[part 2 of 2: packages /ECUCompositionTypes to /EndToEndProtections]
AUTOSAR XML (schema 00050)
package /ECUCompositionTypes
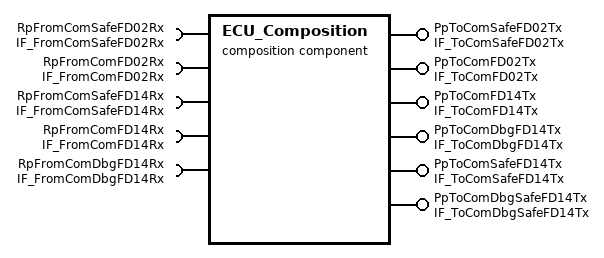
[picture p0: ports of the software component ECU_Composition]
  composition sw component type ECU_Composition
    5 x require port:
      RpFromComSafeFD02Rx: required-interface=IF_FromComSafeFD02Rx
        required-com-specs:
          data-element=PdlPosActual, init-value=1
          data-element=ASCM_Stat, init-value=0
          data-element=ASCM_SysFail, init-value=0
          data-element=ECM_THA_Resp, init-value=0
          data-element=ECM_TRSC_Resp, init-value=0
          data-element=EngineSts_W, init-value=3
          data-element=ESS_ENG_ST_W, init-value=15
          data-element=FL_Lvl, init-value=254
          data-element=FL_Lvl_Adj, init-value=0
          data-element=FR_Lvl, init-value=254
          data-element=FR_Lvl_Adj, init-value=0
          data-element=GearEngagedForDisplay, init-value=31
          data-element=HU_TRSC_EnableBtn_Sts, init-value=0
          data-element=RL_Lvl, init-value=254
          data-element=RL_Lvl_Adj, init-value=0
          data-element=RR_Lvl, init-value=254
          data-element=RR_Lvl_Adj, init-value=0
          {data-element=VIN_DATA, init-value=[rule-based-values={rule=FILL_UNTIL_END, rule-arguments=0}]}
          data-element=VIN_MSG, init-value=3
          data-element=Active_Park_Mode, init-value=0
          data-element=Active_Park_Prox_Chime, init-value=0
          data-element=APARequestSts, init-value=0
          data-element=Backup_Cam_Delay, init-value=0
          data-element=Brk_Stat, init-value=0
          data-element=CmdIgnSts, init-value=0
          data-element=DriverDoorSts, init-value=0
          data-element=DynamicGrid, init-value=1
          data-element=ExternalTemperature, init-value=0
          data-element=FT_PAMRequestSts, init-value=0
          data-element=Fwrd_Cam_Guidelines, init-value=0
          data-element=GearEngaged, init-value=0
          data-element=HAS_Status_C2, init-value=0
          data-element=LanguageSelection, init-value=0
          data-element=LatAcceleration_BSM, init-value=4095
          data-element=LHRDoorSts, init-value=0
          data-element=LongAcceleration_BSM, init-value=4095
          data-element=LwsAngle, init-value=0
          data-element=LwsAngleType, init-value=0
          data-element=LwsSpeed, init-value=0
          data-element=MRM_STATUS_C2, init-value=0
          data-element=PamChimeVolumeFront, init-value=1
          data-element=PamChimeVolumeRear, init-value=1
          data-element=PAMRequestSts, init-value=0
          data-element=PsngrDoorSts, init-value=0
          data-element=Rear_Brk_Asst, init-value=0
          data-element=RHatchSts, init-value=0
          data-element=RHRDoorSts, init-value=0
          data-element=ShiftLeverPosition, init-value=0
          data-element=SVC_Guidelines, init-value=0
          data-element=TargetGear, init-value=15
          data-element=TCASERANGESTATUS, init-value=0
          data-element=TGW_CAMERA_DISP_STAT, init-value=0
          data-element=TrailerConnectionSts, init-value=0
          data-element=TRANS_ADAS_Inhibit, init-value=0
          data-element=TransmissionSailingSts, init-value=0
          data-element=VehicleSpeedVSOSig, init-value=0
          data-element=YawRate_BSM, init-value=4095
          data-element=CameraDisplaySts2, init-value=0
          data-element=CM_TCH_STAT, init-value=0
          data-element=CM_TCH_X_COORD, init-value=0
          data-element=CM_TCH_Y_COORD, init-value=0
          data-element=ITBM_TrlrStat, init-value=0
          data-element=Shifter_ADAS_Inhibit, init-value=0
          data-element=ShiftLeverPositionReq, init-value=0
          data-element=EPS_SteeringTouchStat, init-value=0
          data-element=EPS_SteeringTouq_Resp, init-value=0
          data-element=EPS_THA_DriverTorqueOverride, init-value=0
          data-element=EPS_THA_SteeringTorqueResp, init-value=0
          data-element=THA_SteeringTouchStat, init-value=0
      RpFromComFD02Rx: required-interface=IF_FromComFD02Rx
        required-com-specs:
          data-element=Altitude_RMSE_C2, init-value=255
          data-element=Battery_Volt_1, init-value=0
          data-element=BSM_THA_Brk_Resp, init-value=0
          data-element=CurrentCanNMState_FD01_BCM, init-value=0
          data-element=CurrentCanNMState_FD01_SGW, init-value=0
          data-element=CurrentCanNMState_FD02_BCM, init-value=0
          data-element=CurrentCanNMState_FD02_BSM2, init-value=0
          data-element=CurrentCanNMState_FD02_CADM2, init-value=0
          data-element=CurrentCanNMState_FD02_EPS, init-value=0
          data-element=CurrentCanNMState_FD02_ORC, init-value=0
          data-element=CurrentCanNMState_FD02_SGW, init-value=0
          data-element=CurrentCanNMState_FD02_TRLR_REV, init-value=0
          data-element=CurrentCanNMState_FD03_BCM, init-value=0
          data-element=CurrentCanNMState_FD03_SGW, init-value=0
          data-element=CurrentCanNMState_FD04_BCM, init-value=0
          data-element=CurrentCanNMState_FD08_SGW, init-value=0
          data-element=CurrentCanNMState_FD11_SGW, init-value=0
          data-element=CurrentFailSts_FD01_BCM, init-value=0
          data-element=CurrentFailSts_FD01_SGW, init-value=0
          data-element=CurrentFailSts_FD02_BCM, init-value=0
          data-element=CurrentFailSts_FD02_BSM2, init-value=0
          data-element=CurrentFailSts_FD02_CADM2, init-value=0
          data-element=CurrentFailSts_FD02_EPS, init-value=0
          data-element=CurrentFailSts_FD02_ORC, init-value=0
          data-element=CurrentFailSts_FD02_SGW, init-value=0
          data-element=CurrentFailSts_FD02_TRLR_REV, init-value=0
          data-element=CurrentFailSts_FD03_BCM, init-value=0
          data-element=CurrentFailSts_FD03_SGW, init-value=0
          data-element=CurrentFailSts_FD04_BCM, init-value=0
          data-element=CurrentFailSts_FD08_SGW, init-value=0
          data-element=CurrentFailSts_FD11_SGW, init-value=0
          data-element=DeltaTimestamp_IMUdata, init-value=255
          data-element=DES_FD01_BCM, init-value=0
          data-element=DES_FD01_SGW, init-value=0
          data-element=DES_FD02_BCM, init-value=0
          data-element=DES_FD02_BSM2, init-value=0
          data-element=DES_FD02_CADM2, init-value=0
          data-element=DES_FD02_EPS, init-value=0
          data-element=DES_FD02_ORC, init-value=0
          data-element=DES_FD02_SGW, init-value=0
          data-element=DES_FD02_TRLR_REV, init-value=0
          data-element=DES_FD03_BCM, init-value=0
          data-element=DES_FD03_SGW, init-value=0
          data-element=DES_FD04_BCM, init-value=0
          data-element=DES_FD08_SGW, init-value=0
          data-element=DES_FD11_SGW, init-value=0
          data-element=Digit_{01..11}, init-value=0
          data-element=EOL_FD01_BCM, init-value=0
          data-element=EOL_FD01_SGW, init-value=0
          data-element=EOL_FD02_BCM, init-value=0
          data-element=EOL_FD02_BSM2, init-value=0
          data-element=EOL_FD02_CADM2, init-value=0
          data-element=EOL_FD02_EPS, init-value=0
          data-element=EOL_FD02_ORC, init-value=0
          data-element=EOL_FD02_SGW, init-value=0
          data-element=EOL_FD02_TRLR_REV, init-value=0
          data-element=EOL_FD03_BCM, init-value=0
          data-element=EOL_FD03_SGW, init-value=0
          data-element=EOL_FD04_BCM, init-value=0
          data-element=EOL_FD08_SGW, init-value=0
          data-element=EOL_FD11_SGW, init-value=0
          data-element=EPBSts, init-value=0
          data-element=GenericFailSts_FD01_BCM, init-value=0
          data-element=GenericFailSts_FD01_SGW, init-value=0
          data-element=GenericFailSts_FD02_BCM, init-value=0
          data-element=GenericFailSts_FD02_BSM2, init-value=0
          data-element=GenericFailSts_FD02_CADM2, init-value=0
          data-element=GenericFailSts_FD02_EPS, init-value=0
          data-element=GenericFailSts_FD02_ORC, init-value=0
          data-element=GenericFailSts_FD02_SGW, init-value=0
          data-element=GenericFailSts_FD02_TRLR_REV, init-value=0
          data-element=GenericFailSts_FD03_BCM, init-value=0
          data-element=GenericFailSts_FD03_SGW, init-value=0
          data-element=GenericFailSts_FD04_BCM, init-value=0
          data-element=GenericFailSts_FD08_SGW, init-value=0
          data-element=GenericFailSts_FD11_SGW, init-value=0
          data-element=Heading_Angle_C2, init-value=65535
          data-element=IgnitionOnCounter, init-value=0
          data-element=LatAcceleration_C2, init-value=4095
          data-element=LatAccelerationOffset_BSM, init-value=255
          data-element=Latitude_RMSE_C2, init-value=255
          data-element=LHF_FastPulseCounter, init-value=0
          data-element=LHF_Spin, init-value=0
          data-element=LHFWheelSpeed, init-value=0
          data-element=LHR_FastPulseCounter, init-value=0
          data-element=LHR_Spin, init-value=0
          data-element=LHRWheelSpeed, init-value=0
          data-element=LongAcceleration_C2, init-value=4095
          data-element=LongAccelerationOffset_BSM, init-value=255
          data-element=Longitude_RMSE_C2, init-value=255
          data-element=OperationalModeSts, init-value=0
          data-element=Pitch_RMSE_C2, init-value=255
          data-element=PitchRate_C2, init-value=4095
          data-element=PreviousCanNMState_FD01_BCM, init-value=0
          data-element=PreviousCanNMState_FD01_SGW, init-value=0
          data-element=PreviousCanNMState_FD02_BCM, init-value=0
          data-element=PreviousCanNMState_FD02_BSM2, init-value=0
          data-element=PreviousCanNMState_FD02_CADM2, init-value=0
          data-element=PreviousCanNMState_FD02_EPS, init-value=0
          data-element=PreviousCanNMState_FD02_ORC, init-value=0
          data-element=PreviousCanNMState_FD02_SGW, init-value=0
          data-element=PreviousCanNMState_FD02_TRLR_REV, init-value=0
          data-element=PreviousCanNMState_FD03_BCM, init-value=0
          data-element=PreviousCanNMState_FD03_SGW, init-value=0
          data-element=PreviousCanNMState_FD04_BCM, init-value=0
          data-element=PreviousCanNMState_FD08_SGW, init-value=0
          data-element=PreviousCanNMState_FD11_SGW, init-value=0
          data-element=REF_VEH_SPEED, init-value=1023
          data-element=RemStActvSts, init-value=0
          data-element=RHF_FastPulseCounter, init-value=0
          data-element=RHF_Spin, init-value=0
          data-element=RHFWheelSpeed, init-value=0
          data-element=RHR_FastPulseCounter, init-value=0
          data-element=RHR_Spin, init-value=0
          data-element=RHRWheelSpeed, init-value=0
          data-element=Roll_RMSE_C2, init-value=255
          data-element=RollRate_C2, init-value=4095
          data-element=SBR1RowDriverSeatSts, init-value=3
          data-element=StayActiveSource_FD01_BCM, init-value=0
          data-element=StayActiveSource_FD01_SGW, init-value=0
          data-element=StayActiveSource_FD02_BCM, init-value=0
          data-element=StayActiveSource_FD02_BSM2, init-value=0
          data-element=StayActiveSource_FD02_CADM2, init-value=0
          data-element=StayActiveSource_FD02_EPS, init-value=0
          data-element=StayActiveSource_FD02_ORC, init-value=0
          data-element=StayActiveSource_FD02_SGW, init-value=0
          data-element=StayActiveSource_FD02_TRLR_REV, init-value=0
          data-element=StayActiveSource_FD03_BCM, init-value=0
          data-element=StayActiveSource_FD03_SGW, init-value=0
          data-element=StayActiveSource_FD04_BCM, init-value=0
          data-element=StayActiveSource_FD08_SGW, init-value=0
          data-element=StayActiveSource_FD11_SGW, init-value=0
          data-element=TotalOdometer, init-value=0
          data-element=TRSC_CenterBtn_Sts, init-value=0
          data-element=TRSC_EnableBtn_Sts, init-value=0
          data-element=TRSC_RawKnob, init-value=0
          data-element=TurnIndicatorSts, init-value=0
          data-element=VehicleStandStillSts, init-value=1
          data-element=VerticalAcceleration_C2, init-value=4095
          data-element=WakeupSource_FD01_ADCM, init-value=0
          data-element=WakeupSource_FD01_BCM, init-value=0
          data-element=WakeupSource_FD01_SGW, init-value=0
          data-element=WakeupSource_FD02_BCM, init-value=0
          data-element=WakeupSource_FD02_BSM2, init-value=0
          data-element=WakeupSource_FD02_CADM2, init-value=0
          data-element=WakeupSource_FD02_EPS, init-value=0
          data-element=WakeupSource_FD02_ORC, init-value=0
          data-element=WakeupSource_FD02_SGW, init-value=0
          data-element=WakeupSource_FD02_TRLR_REV, init-value=0
          data-element=WakeupSource_FD03_BCM, init-value=0
          data-element=WakeupSource_FD03_SGW, init-value=0
          data-element=WakeupSource_FD04_BCM, init-value=0
          data-element=WakeupSource_FD08_SGW, init-value=0
          data-element=WakeupSource_FD11_SGW, init-value=0
          data-element=YawRate_C2, init-value=4095
          data-element=YawRate_RMSE_C2, init-value=255
      RpFromComSafeFD14Rx: required-interface=IF_FromComSafeFD14Rx
        required-com-specs:
          data-element=FD14_PdlPosActual, init-value=1
          data-element=FD14_ECM_THA_Resp, init-value=0
          data-element=FD14_ECM_TRSC_Resp, init-value=0
          data-element=FD14_EngineSts_W, init-value=3
          data-element=FD14_ESS_ENG_ST_W, init-value=15
          data-element=FD14_ACC_Systemsts, init-value=0
          data-element=FD14_Brk_Stat, init-value=0
          data-element=FD14_BrkPdl_Stat, init-value=3
          data-element=FD14_BrkTrq, init-value=32767
          data-element=FD14_BrkTrq_Driver, init-value=32767
          data-element=FD14_BSM_THA_Brk_Resp, init-value=0
          data-element=FD14_EPBSts, init-value=0
          data-element=FD14_EPS_HandsOnRecognition, init-value=0
          data-element=FD14_ESC_TRSC_Brk_Resp, init-value=0
          data-element=FD14_ExternalBrkRequestsDisabled, init-value=0
          data-element=FD14_HAS_Status, init-value=0
          data-element=FD14_LatAcceleration_BSM, init-value=4095
          data-element=FD14_LatAccelerationFailSts_BSM, init-value=0
          data-element=FD14_LatAccelerationOffset_BSM, init-value=255
          data-element=FD14_LHF_FastPulseCounter, init-value=0
          data-element=FD14_LHF_Spin, init-value=0
          data-element=FD14_LHF_WheelSensorFailSts, init-value=0
          data-element=FD14_LHFWheelSpeed, init-value=0
          data-element=FD14_LHR_FastPulseCounter, init-value=0
          data-element=FD14_LHR_Spin, init-value=0
          data-element=FD14_LHR_WheelSensorFailSts, init-value=0
          data-element=FD14_LHRWheelSpeed, init-value=0
          data-element=FD14_LongAcceleration_BSM, init-value=4095
          data-element=FD14_LongAccelerationFailSts_BSM, init-value=0
          data-element=FD14_LongAccelerationOffset_BSM, init-value=255
          data-element=FD14_LwsAngle, init-value=0
          data-element=FD14_LwsAngleType, init-value=0
          data-element=FD14_LwsSpeed, init-value=0
          data-element=FD14_PAM_Brk_Rq_RspSts, init-value=0
          data-element=FD14_ParkingGearShiftReq_BSM, init-value=0
          data-element=FD14_ParkingInterventionSts, init-value=0
          data-element=FD14_REF_VEH_SPEED, init-value=1023
          data-element=FD14_RHF_FastPulseCounter, init-value=0
          data-element=FD14_RHF_Spin, init-value=0
          data-element=FD14_RHF_WheelSensorFailSts, init-value=0
          data-element=FD14_RHFWheelSpeed, init-value=0
          data-element=FD14_RHR_FastPulseCounter, init-value=0
          data-element=FD14_RHR_Spin, init-value=0
          data-element=FD14_RHR_WheelSensorFailSts, init-value=0
          data-element=FD14_RHRWheelSpeed, init-value=0
          data-element=FD14_Slope, init-value=0
          data-element=FD14_SPM_Lat_Ctrl_ResponseSts, init-value=0
          data-element=FD14_Steering_Column_Torque, init-value=0
          data-element=FD14_VehicleSpeedVSOSig, init-value=0
          data-element=FD14_VehicleSpeedVSOSig_B2, init-value=0
          data-element=FD14_VehicleStandStillSts, init-value=1
          data-element=FD14_YawRate_BSM, init-value=4095
          data-element=FD14_YawRateFailSts_BSM, init-value=0
          data-element=FD14_EPS_SteeringTouchStat, init-value=0
          data-element=FD14_EPS_SteeringTouq_Resp, init-value=0
          data-element=FD14_EPS_THA_DriverTorqueOverride, init-value=0
          data-element=FD14_EPS_THA_SteeringTorqueResp, init-value=0
          data-element=FD14_THA_SteeringTouchStat, init-value=0
      RpFromComFD14Rx: required-interface=IF_FromComFD14Rx
        required-com-specs:
          data-element=FD14_Accel_Pedal_Override, init-value=0
          data-element=FD14_DriverReq_AxleTrq_Enabled_BSM, init-value=0
          data-element=FD14_PPPA_TrqEnblRq_Allowed, init-value=0
      RpFromComDbgFD14Rx: required-interface=IF_FromComDbgFD14Rx
        required-com-specs:
          {data-element=FD14_RawPntDebugSignal, init-value=[rule-based-values={rule=FILL_UNTIL_END, rule-arguments=0}]}
          data-element=FD14_UssParkingModeSignal, init-value=0
    6 x provide port:
      PpToComSafeFD02Tx: provided-interface=IF_ToComSafeFD02Tx
        provided-com-specs:
          data-element=Reserved_for_functional_safety, init-value=0
          data-element=Segment_1_Confidence, init-value=0
          data-element=Segment_1_ID, init-value=0
          data-element=Segment_1_X1, init-value=0
          data-element=Segment_1_X2, init-value=0
          data-element=Segment_1_Y1, init-value=0
          data-element=Segment_1_Y2, init-value=0
          data-element=Segment_2_Confidence, init-value=0
          data-element=Segment_2_ID, init-value=0
          data-element=Segment_2_X1, init-value=0
          data-element=Segment_2_X2, init-value=0
          data-element=Segment_2_Y1, init-value=0
          data-element=Segment_2_Y2, init-value=0
          data-element=Segment_3_Confidence, init-value=0
          data-element=Segment_3_ID, init-value=0
          data-element=Segment_3_X1, init-value=0
          data-element=Segment_3_X2, init-value=0
          data-element=Segment_3_Y1, init-value=0
          data-element=Segment_3_Y2, init-value=0
          data-element=Segment_4_Confidence, init-value=0
          data-element=Segment_4_ID, init-value=0
          data-element=Segment_4_X1, init-value=0
          data-element=Segment_4_X2, init-value=0
          data-element=Segment_4_Y1, init-value=0
          data-element=Segment_4_Y2, init-value=0
          data-element=Segment_5_Confidence, init-value=0
          data-element=Segment_5_ID, init-value=0
          data-element=Segment_5_X1, init-value=0
          data-element=Segment_5_X2, init-value=0
          data-element=Segment_5_Y1, init-value=0
          data-element=Segment_5_Y2, init-value=0
          data-element=Segment_6_Confidence, init-value=0
          data-element=Segment_6_ID, init-value=0
          data-element=Segment_6_X1, init-value=0
          data-element=Segment_6_X2, init-value=0
          data-element=Segment_6_Y1, init-value=0
          data-element=Segment_6_Y2, init-value=0
          data-element=Segment_7_Confidence, init-value=0
          data-element=Segment_7_ID, init-value=0
          data-element=Segment_7_X1, init-value=0
          data-element=Segment_7_X2, init-value=0
          data-element=Segment_7_Y1, init-value=0
          data-element=Segment_7_Y2, init-value=0
          data-element=Segment_8_Confidence, init-value=0
          data-element=Segment_8_ID, init-value=0
          data-element=Segment_8_X1, init-value=0
          data-element=Segment_8_X2, init-value=0
          data-element=Segment_8_Y1, init-value=0
          data-element=Segment_8_Y2, init-value=0
          data-element=Camera_Status, init-value=0
          data-element=Cntr_ADAS_FD_LANES_1, init-value=0
          data-element=Cntr_ADAS_FD_LANES_2, init-value=0
          data-element=FOD_Confidence, init-value=0
          data-element=Frame_Index_Lanes_1, init-value=0
          data-element=Frame_Index_Lanes_2, init-value=0
          data-element=Health_Front_Object_Detection, init-value=0
          data-element=Health_Lane_Detection, init-value=0
          data-element=Line_1_Confidence, init-value=0
          data-element=Line_1_Curvature, init-value=0
          data-element=Line_1_Curvature_Rate, init-value=0
          data-element=Line_1_End_Range, init-value=0
          data-element=Line_1_Heading, init-value=0
          data-element=Line_1_Offset, init-value=0
          data-element=Line_1_Start_Range, init-value=0
          data-element=Line_1_Type, init-value=0
          data-element=Line_2_Confidence, init-value=0
          data-element=Line_2_Curvature, init-value=0
          data-element=Line_2_Curvature_Rate, init-value=0
          data-element=Line_2_End_Range, init-value=0
          data-element=Line_2_Heading, init-value=0
          data-element=Line_2_Offset, init-value=0
          data-element=Line_2_Start_Range, init-value=0
          data-element=Line_2_Type, init-value=0
          data-element=Line_3_Confidence, init-value=0
          data-element=Line_3_Curvature, init-value=0
          data-element=Line_3_Curvature_Rate, init-value=0
          data-element=Line_3_End_Range, init-value=0
          data-element=Line_3_Heading, init-value=0
          data-element=Line_3_Offset, init-value=0
          data-element=Line_3_Start_Range, init-value=0
          data-element=Line_3_Type, init-value=0
          data-element=Line_4_Confidence, init-value=0
          data-element=Line_4_Curvature, init-value=0
          data-element=Line_4_Curvature_Rate, init-value=0
          data-element=Line_4_End_Range, init-value=0
          data-element=Line_4_Heading, init-value=0
          data-element=Line_4_Offset, init-value=0
          data-element=Line_4_Start_Range, init-value=0
          data-element=Line_4_Type, init-value=0
          {data-element=MAC_ADAS_FD_LANES_1, init-value=[rule-based-values={rule=FILL_UNTIL_END, rule-arguments=0}]}
          {data-element=MAC_ADAS_FD_LANES_2, init-value=[rule-based-values={rule=FILL_UNTIL_END, rule-arguments=0}]}
          data-element=Alert_CHF, init-value=0
          data-element=Alert_CHR, init-value=0
          data-element=Alert_LHF, init-value=0
          data-element=Alert_LHR, init-value=0
          data-element=Alert_RHF, init-value=0
          data-element=Alert_RHR, init-value=0
          data-element=AUXCamsRQSts, init-value=0
          data-element=ChimeActivation_LHF, init-value=0
          data-element=ChimeActivation_LHR, init-value=0
          data-element=ChimeActivation_RHF, init-value=0
          data-element=ChimeActivation_RHR, init-value=0
          data-element=DisplayView2, init-value=0
          data-element=FrontSensorSts, init-value=0
          data-element=FT_PAM_LedControlSts, init-value=0
          data-element=Graphic_CHF, init-value=0
          data-element=Graphic_CHR, init-value=0
          data-element=Graphic_LHF, init-value=0
          data-element=Graphic_LHR, init-value=0
          data-element=Graphic_RHF, init-value=0
          data-element=Graphic_RHR, init-value=0
          data-element=HMICode, init-value=0
          data-element=ImageDefeatRQSts, init-value=0
          data-element=MoreCamsRQSts, init-value=0
          data-element=PAM_CHIME_REP_RATESts, init-value=0
          data-element=PAM_CHIME_TYPE, init-value=0
          data-element=PAM_LedControlSts, init-value=0
          data-element=PAM_Off_Status, init-value=0
          data-element=PAM_Off_Status_2BT, init-value=0
          data-element=PAM_PopUpRqst, init-value=0
          data-element=PAM_Volume, init-value=0
          data-element=PAMSystemFault, init-value=0
          data-element=ParkingManeuverActive, init-value=0
          data-element=PPPA_TurnIndicatorRqst, init-value=0
          data-element=RearSensorSts, init-value=0
          data-element=RR_PAM_Brk_RqSts, init-value=0
          data-element=RR_PAM_Dist, init-value=0
          data-element=RR_PAM_StopControlSts, init-value=0
          data-element=SPM_LedControlSts, init-value=0
          data-element=SPM_Screen_Rqst, init-value=0
          data-element=SPMControlSts, init-value=0
          data-element=SPMFailSts, init-value=0
          data-element=SPMSystemFault, init-value=0
          data-element=TRSC_LED_Stat, init-value=0
      PpToComFD02Tx: provided-interface=IF_ToComFD02Tx
        provided-com-specs:
          data-element=CurrentCanNMState_FD02_PAM, init-value=0
          data-element=CurrentFailSts_FD02_PAM, init-value=0
          data-element=DES_FD02_PAM, init-value=0
          data-element=Digit_{01..11}_PAM, init-value=0
          data-element=EOL_FD02_PAM, init-value=0
          data-element=GenericFailSts_FD02_PAM, init-value=0
          {data-element=N_PDU, init-value=[rule-based-values={rule=FILL_UNTIL_END, rule-arguments=0}]}
          data-element=PreviousCanNMState_FD02_PAM, init-value=0
          {data-element=StayActiveSource_FD02_PAM, init-value=[rule-based-values={rule=FILL_UNTIL_END, rule-arguments=0}]}
          data-element=THA_EPB_Req, init-value=0
          data-element=THA_Speed_Limit, init-value=0
          data-element=THA_SpeedLimit_Req, init-value=0
          data-element=THA_STAT, init-value=0
          data-element=THA_SteeringDamping, init-value=78.125
          data-element=THA_SteeringTorqueInfo, init-value=0
          data-element=THA_SteeringTorqueReq, init-value=0
          data-element=Trailer_Angle, init-value=0
          data-element=Trailer_Angle_Sign, init-value=0
          data-element=Trailer_Calibration, init-value=0
          data-element=TrlrHitchLight_Cntrl, init-value=0
          data-element=TRSC_PopupDisp_Info, init-value=0
          data-element=TRSC_SpeedLimit_Req, init-value=0
          data-element=TRSC_STAT, init-value=1
          data-element=TRSC_SteeringDamping, init-value=100
          data-element=TRSC_SteeringTorqueInfo, init-value=0
          data-element=TRSC_SteeringTorqueReq, init-value=0
          data-element=TRSC_VehicleStop_Req, init-value=3
          data-element=TRSCMoreCamRQSts, init-value=0
          data-element=WakeupSource_FD02_PAM, init-value=0
          data-element=TRSC_PopupDisp_Info2, init-value=0
      PpToComFD14Tx: provided-interface=IF_ToComFD14Tx
        provided-com-specs:
          data-element=FD14_THA_EPB_Req, init-value=0
          data-element=FD14_THA_Speed_Limit, init-value=0
          data-element=FD14_THA_SpeedLimit_Req, init-value=0
          data-element=FD14_THA_STAT, init-value=0
          data-element=FD14_THA_SteeringDamping, init-value=100
          data-element=FD14_THA_SteeringTorqueInfo, init-value=1024
          data-element=FD14_THA_SteeringTorqueReq, init-value=0
          data-element=FD14_TRSC_SpeedLimit_Req, init-value=0
          data-element=FD14_TRSC_STAT, init-value=1
          data-element=FD14_TRSC_SteeringDamping, init-value=100
          data-element=FD14_TRSC_SteeringTorqueInfo, init-value=1024
          data-element=FD14_TRSC_SteeringTorqueReq, init-value=0
          data-element=FD14_TRSC_VehicleStop_Req, init-value=3
      PpToComDbgFD14Tx: provided-interface=IF_ToComDbgFD14Tx
        provided-com-specs:
          FD14_ZoomPlusIcon_b
          FD14_ZoomMinusIcon_b
          FD14_ZoomFactor_u8
          FD14_ZoomButtonDisable_b
          FD14_Z_f32_EOL_Right
          FD14_Z_f32_EOL_Rear
          FD14_Z_f32_EOL_Left
          FD14_Z_f32_EOL_Front
          FD14_Z_f32_Current_Right
          FD14_Z_f32_Current_Rear
          FD14_Yaw_f32_SC_Right
          FD14_Yaw_f32_SC_Rear
          FD14_Yaw_f32_SC_Left
          FD14_Yaw_f32_SC_Front
          FD14_Yaw_f32_OC_Right
          FD14_Yaw_f32_OC_Rear
          FD14_Yaw_f32_OC_Left
          FD14_Yaw_f32_OC_Front
          FD14_Yaw_f32_EOL_Right
          FD14_Yaw_f32_EOL_Rear
          FD14_Yaw_f32_EOL_Left
          FD14_Yaw_f32_EOL_Front
          FD14_Yaw_f32_Current_Right
          FD14_Yaw_f32_Current_Rear
          FD14_Y_f32_EOL_Right
          FD14_Y_f32_EOL_Rear
          FD14_Y_f32_EOL_Left
          FD14_Y_f32_EOL_Front
          FD14_Y_f32_Current_Right
          FD14_Y_f32_Current_Rear
          FD14_XIcon_b
          FD14_X_f32_EOL_Right
          FD14_X_f32_EOL_Rear
          FD14_X_f32_EOL_Left
          FD14_X_f32_EOL_Front
          FD14_X_f32_Current_Right
          FD14_X_f32_Current_Rear
          FD14_X_BTN_PRESSED_b
          FD14_View_Error_e
          FD14_vehicleSpeed_f32
          FD14_vehicleLine_e
          FD14_ValidFeatures_Right_u32
          FD14_ValidFeatures_Rear_u32
          FD14_ValidFeatures_Left_u32
          FD14_ValidFeatures_Front_u32
          FD14_USS_MPAZoneF03
          FD14_USS_MPAZoneF02
          FD14_USS_MPAZoneF01
          FD14_USS_MPAZoneF00
          FD14_USS_MPAZoneB03
          FD14_USS_MPAZoneB02
          FD14_USS_MPAZoneB01
          FD14_USS_MPAZoneB00
          FD14_turnaroundSubState
          FD14_Tstr_SD_RSR_Unfiltered_DirDist2
          FD14_Tstr_SD_RSR_Unfiltered_DirDist1
          FD14_Tstr_SD_RSR_SensorBlkgSetCounter
          FD14_Tstr_SD_RSR_SensorBlkgClrCounter
          FD14_Tstr_SD_RSR_Ringtime_us
          FD14_Tstr_SD_RSR_RingFreq
          FD14_Tstr_SD_RSR_EchoHeight_adc
          FD14_Tstr_SD_RSR_DrvFreq
          FD14_Tstr_SD_RSL_Unfiltered_DirDist2
          FD14_Tstr_SD_RSL_Unfiltered_DirDist1
          FD14_Tstr_SD_RSL_SensorBlkgSetCounter
          FD14_Tstr_SD_RSL_SensorBlkgClrCounter
          FD14_Tstr_SD_RSL_Ringtime_us
          FD14_Tstr_SD_RSL_RingFreq
          FD14_Tstr_SD_RSL_EchoHeight_adc
          FD14_Tstr_SD_RSL_DrvFreq
          FD14_Tstr_SD_ROR_Unfiltered_DirDist2
          FD14_Tstr_SD_ROR_Unfiltered_DirDist1
          FD14_Tstr_SD_ROR_SensorBlkgSetCounter
          FD14_Tstr_SD_ROR_SensorBlkgClrCounter
          FD14_Tstr_SD_ROR_Ringtime_us
          FD14_Tstr_SD_ROR_RingFreq
          FD14_Tstr_SD_ROR_EchoHeight_adc
          FD14_Tstr_SD_ROR_DrvFreq
          FD14_Tstr_SD_ROL_Unfiltered_DirDist2
          FD14_Tstr_SD_ROL_Unfiltered_DirDist1
          FD14_Tstr_SD_ROL_SensorBlkgSetCounter
          FD14_Tstr_SD_ROL_SensorBlkgClrCounter
          FD14_Tstr_SD_ROL_Ringtime_us
          FD14_Tstr_SD_ROL_RingFreq
          FD14_Tstr_SD_ROL_EchoHeight_adc
          FD14_Tstr_SD_ROL_DrvFreq
          FD14_Tstr_SD_RIR_Unfiltered_DirDist2
          FD14_Tstr_SD_RIR_Unfiltered_DirDist1
          FD14_Tstr_SD_RIR_SensorBlkgSetCounter
          FD14_Tstr_SD_RIR_SensorBlkgClrCounter
          FD14_Tstr_SD_RIR_Ringtime_us
          FD14_Tstr_SD_RIR_RingFreq
          FD14_Tstr_SD_RIR_EchoHeight_adc
          FD14_Tstr_SD_RIR_DrvFreq
          FD14_Tstr_SD_RIL_Unfiltered_DirDist2
          FD14_Tstr_SD_RIL_Unfiltered_DirDist1
          FD14_Tstr_SD_RIL_SensorBlkgSetCounter
          FD14_Tstr_SD_RIL_SensorBlkgClrCounter
          FD14_Tstr_SD_RIL_Ringtime_us
          FD14_Tstr_SD_RIL_RingFreq
          FD14_Tstr_SD_RIL_EchoHeight_adc
          FD14_Tstr_SD_RIL_DrvFreq
          FD14_Tstr_SD_FSR_Unfiltered_DirDist2
          FD14_Tstr_SD_FSR_Unfiltered_DirDist1
          FD14_Tstr_SD_FSR_SensorBlkgSetCounter
          FD14_Tstr_SD_FSR_SensorBlkgClrCounter
          FD14_Tstr_SD_FSR_Ringtime_us
          FD14_Tstr_SD_FSR_RingFreq
          FD14_Tstr_SD_FSR_EchoHeight_adc
          FD14_Tstr_SD_FSR_DrvFreq
          FD14_Tstr_SD_FSL_Unfiltered_DirDist2
          FD14_Tstr_SD_FSL_Unfiltered_DirDist1
          FD14_Tstr_SD_FSL_SensorBlkgSetCounter
          FD14_Tstr_SD_FSL_SensorBlkgClrCounter
          FD14_Tstr_SD_FSL_Ringtime_us
          FD14_Tstr_SD_FSL_RingFreq
          FD14_Tstr_SD_FSL_EchoHeight_adc
          FD14_Tstr_SD_FSL_DrvFreq
          FD14_Tstr_SD_FOR_Unfiltered_DirDist2
          FD14_Tstr_SD_FOR_Unfiltered_DirDist1
          FD14_Tstr_SD_FOR_SensorBlkgSetCounter
          FD14_Tstr_SD_FOR_SensorBlkgClrCounter
          FD14_Tstr_SD_FOR_Ringtime_us
          FD14_Tstr_SD_FOR_RingFreq
          FD14_Tstr_SD_FOR_EchoHeight_adc
          FD14_Tstr_SD_FOR_DrvFreq
          FD14_Tstr_SD_FOL_Unfiltered_DirDist2
          FD14_Tstr_SD_FOL_Unfiltered_DirDist1
          FD14_Tstr_SD_FOL_SensorBlkgSetCounter
          FD14_Tstr_SD_FOL_SensorBlkgClrCounter
          FD14_Tstr_SD_FOL_Ringtime_us
          FD14_Tstr_SD_FOL_RingFreq
          FD14_Tstr_SD_FOL_EchoHeight_adc
          FD14_Tstr_SD_FOL_DrvFreq
          FD14_Tstr_SD_FIR_Unfiltered_DirDist2
          FD14_Tstr_SD_FIR_Unfiltered_DirDist1
          FD14_Tstr_SD_FIR_SensorBlkgSetCounter
          FD14_Tstr_SD_FIR_SensorBlkgClrCounter
          FD14_Tstr_SD_FIR_Ringtime_us
          FD14_Tstr_SD_FIR_RingFreq
          FD14_Tstr_SD_FIR_EchoHeight_adc
          FD14_Tstr_SD_FIR_DrvFreq
          FD14_Tstr_SD_FIL_Unfiltered_DirDist2
          FD14_Tstr_SD_FIL_Unfiltered_DirDist1
          FD14_Tstr_SD_FIL_SensorBlkgSetCounter
          FD14_Tstr_SD_FIL_SensorBlkgClrCounter
          FD14_Tstr_SD_FIL_Ringtime_us
          FD14_Tstr_SD_FIL_RingFreq
          FD14_Tstr_SD_FIL_EchoHeight_adc
          FD14_Tstr_SD_FIL_DrvFreq
          FD14_TrscTrailerRed
          FD14_TrscStatus
          FD14_trscStat_e
          FD14_TrscOvl
          FD14_TrscJackKnifeRed
          FD14_TrscJackKnifeOrange
          FD14_transEquipped_e
          FD14_TrailerWheelBase
          FD14_TrailerConnectionStatus
          FD14_Trailercalinfo
          FD14_TrailerCalibrationStatus
          FD14_trailerCalibrationDelay
          FD14_trailerCalibrationCount
          FD14_TrailerCalFailInfo
          FD14_TrailerAngleSign
          FD14_trailerAngle
          FD14_Trailer_tracking_confidence
          FD14_Trailer_Recognition_Confidence
          FD14_Total_lines_count
          FD14_TopViewRearDynamics_b
          FD14_TopViewFrontDynamics_b
          FD14_TopViewBlack_b
          FD14_TopVideoBlanked_b
          FD14_TopRearButtonSelect_b
          FD14_TopRearButtonNoSelect_b
          FD14_TopFrontButtonSelect_b
          FD14_TopFrontButtonNoSelect_b
          FD14_TimeStamp_SystemStatus
          FD14_THATriangleOverlay
          FD14_THAStartButton
          FD14_THAProgressBar
          FD14_THACouplerBulletIcon
          FD14_THAConfirmButton
          FD14_THAButtonSelectable
          FD14_THAButtonGrey
          FD14_tgwDispStatus_e
          FD14_tchScrnStatus_e
          FD14_tchScrnCoord_s_Y_u16
          FD14_tchScrnCoord_s_X_u16
          FD14_TargetLimitRear_Right_s8
          FD14_TargetLimitRear_Rear_s8
          FD14_TargetLimitRear_Left_s8
          FD14_TargetLimitRear_Front_s8
          FD14_TargetLimitFront_Right_s8
          FD14_TargetLimitFront_Rear_s8
          FD14_TargetLimitFront_Left_s8
          FD14_TargetLimitFront_Front_s8
          FD14_TargetInit_Right_s8
          FD14_TargetInit_Rear_s8
          FD14_TargetInit_Left_s8
          FD14_TargetInit_Front_s8
          FD14_TargetDetectRightRear_Right_s8
          FD14_TargetDetectRightRear_Rear_s8
          FD14_TargetDetectRightRear_Left_s8
          FD14_TargetDetectRightRear_Front_s8
          FD14_TargetDetectRightFront_Right_s8
          FD14_TargetDetectRightFront_Rear_s8
          FD14_TargetDetectRightFront_Left_s8
          FD14_TargetDetectRightFront_Front_s8
          FD14_TargetDetectLeftRear_Right_s8
          FD14_TargetDetectLeftRear_Rear_s8
          FD14_TargetDetectLeftRear_Front_s8
          FD14_TargetDetectLeftFront_Right_s8
          FD14_TargetDetectLeftFront_Rear_s8
          FD14_TargetDetectLeftFront_Left_s8
          FD14_TargetDetectLeftFront_Front_s8
          FD14_TADAngleRate
          FD14_TadAngle
          FD14_SystemStatus
          FD14_SystemMode
          FD14_SVC_Static_Gridlines_Feature_b
          FD14_SVC_FFCV_Gridlines_Feature_b
          FD14_SVC_Dynamic_Gridlines_Feature_b
          FD14_SVC_Delay_Feature_b
          FD14_stUSSParkingSlot6SlotValid
          FD14_stUSSParkingSlot5SlotValid
          FD14_stUSSParkingSlot4SlotValid
          FD14_stUSSParkingSlot4SlotType
          FD14_stUSSParkingSlot4RearRightY
          FD14_stUSSParkingSlot4RearRightX
          FD14_stUSSParkingSlot4FrontLeftY
          FD14_stUSSParkingSlot4FrontLeftX
          FD14_stUSSParkingSlot4DataSlotSide
          FD14_stUSSParkingSlot3SlotValid
          FD14_stUSSParkingSlot2SlotValid
          FD14_stUSSParkingSlot1SlotValid
          FD14_stUSSParkingSlot1SlotType
          FD14_stUSSParkingSlot1RearRightY
          FD14_stUSSParkingSlot1RearRightX
          FD14_stUSSParkingSlot1FrontLeftY
          FD14_stUSSParkingSlot1FrontLeftX
          FD14_stUSSParkingSlot1DataSlotSide
          FD14_stUSSParkingSlot1DataSlotID
          FD14_stUSSLockedSlotDataSlotValid
          FD14_stUSSLockedSlotDataSlotType
          FD14_stUSSLockedSlotDataSlotSide
          FD14_stUSSLockedSlotDataSlotID
          FD14_stUSSLockedSlotDataRearRightY
          FD14_stUSSLockedSlotDataRearRightX
          FD14_stUSSLockedSlotDataFrontLeftY
          FD14_stUSSLockedSlotDataFrontLeftX
          FD14_stRightObjectList4Valid
          FD14_stRightObjectList3Valid
          FD14_stRightObjectList2Valid
          FD14_stRightObjectList1Valid
          FD14_stPLDParkingSlot6SlotValid
          FD14_stPLDParkingSlot5SlotValid
          FD14_stPLDParkingSlot4SlotValid
          FD14_stPLDParkingSlot4SlotType
          FD14_stPLDParkingSlot4RearRightY
          FD14_stPLDParkingSlot4RearRightX
          FD14_stPLDParkingSlot4FrontLeftY
          FD14_stPLDParkingSlot4FrontLeftX
          FD14_stPLDParkingSlot4DataSlotSide
          FD14_stPLDParkingSlot4DataSlotID
          FD14_stPLDParkingSlot3SlotValid
          FD14_stPLDParkingSlot2SlotValid
          FD14_stPLDParkingSlot1SlotValid
          FD14_stPLDParkingSlot1SlotType
          FD14_stPLDParkingSlot1RearRightY
          FD14_stPLDParkingSlot1RearRightX
          FD14_stPLDParkingSlot1FrontLeftY
          FD14_stPLDParkingSlot1FrontLeftX
          FD14_stPLDParkingSlot1DataSlotSide
          FD14_stPLDParkingSlot1DataSlotID
          FD14_stPLDLockedSlotDataSlotValid
          FD14_stPLDLockedSlotDataSlotType
          FD14_stPLDLockedSlotDataSlotSide
          FD14_stPLDLockedSlotDataSlotID
          FD14_stPLDLockedSlotDataRearRightY
          FD14_stPLDLockedSlotDataRearRightX
          FD14_stPLDLockedSlotDataFrontLeftY
          FD14_stPLDLockedSlotDataFrontLeftX
          FD14_stnumPointsR
          FD14_stnumPointsL
          FD14_STM_v_TRGRIGHT_BTN_PRESSED_b
          FD14_STM_v_TRGLEFT_BTN_PRESSED_b
          FD14_STM_v_TRGAUTO_BTN_PRESSED_b
          FD14_stLeftObjectList4Valid
          FD14_stLeftObjectList3Valid
          FD14_stLeftObjectList2Valid
          FD14_stLeftObjectList1Valid
          FD14_stFPAInfoToVCLockedSlotValid
          FD14_stFPAInfoToVCLockedSlotType
          FD14_stFPAInfoToVCLockedSlotSide
          FD14_stFPAInfoToVCLockedSlotRearRghtY
          FD14_stFPAInfoToVCLockedSlotRearRghtX
          FD14_stFPAInfoToVCLockedSlotID
          FD14_stFPAInfoToVCLockedSlotFrntLeftY
          FD14_stFPAInfoToVCLockedSlotFrntLeftX
          FD14_stFPAInfoToHMISlot6Valid
          FD14_stFPAInfoToHMISlot5Valid
          FD14_stFPAInfoToHMISlot4Valid
          FD14_stFPAInfoToHMISlot3Valid
          FD14_stFPAInfoToHMISlot2Valid
          FD14_stFPAInfoToHMISlot1Valid
          FD14_steeringWheelAngle_f32
          FD14_SrvStAngIndOk_b
          FD14_SrvStAngIndNok_b
          FD14_SrvSpOmIndOk_b
          FD14_SrvSpOmIndNok_b
          FD14_SrvPrgBar80Per_b
          FD14_SrvPrgBar60Per_b
          FD14_SrvPrgBar40Per_b
          FD14_SrvPrgBar20Per_b
          FD14_SrvPrgBar100Per_b
          FD14_SrvPrgBar0Per_b
          FD14_SrvLayout_b
          FD14_SrvChkIndRun_b
          FD14_SrvChkIndOk_b
          FD14_SrvChkIndNok_b
          FD14_SrvChkIndCondNok_b
          FD14_SrvCamIndRiPend_b
          FD14_SrvCamIndRiOk_b
          FD14_SrvCamIndRiNone_b
          FD14_SrvCamIndRiNok_b
          FD14_SrvCamIndLePend_b
          FD14_SrvCamIndLeOk_b
          FD14_SrvCamIndLeNone_b
          FD14_SrvCamIndLeNok_b
          FD14_SrvCamIndFrPend_b
          FD14_SrvCamIndFrOk_b
          FD14_SrvCamIndFrNone_b
          FD14_SrvCamIndFrNok_b
          FD14_SrvCamIndBaPend_b
          FD14_SrvCamIndBaOk_b
          FD14_SrvCamIndBaNone_b
          FD14_SrvCamIndBaNok_b
          FD14_SoftBtn_Error_e
          FD14_SnrMeasDataChecksum
          FD14_SnrDat_sRSR_Indir_ROR_cm
          FD14_SnrDat_sRSL_Indir_ROL_cm
          FD14_SnrDat_sROR_Indir_RSR_cm
          FD14_SnrDat_sROR_Indir_RIR_cm
          FD14_SnrDat_sROL_Indir_RSL_cm
          FD14_SnrDat_sROL_Indir_RIL_cm
          FD14_SnrDat_sRIR_Indir_ROR_cm
          FD14_SnrDat_sRIR_Indir_RIL_cm
          FD14_SnrDat_sRIL_Indir_ROL_cm
          FD14_SnrDat_sRIL_Indir_RIR_cm
          FD14_SnrDat_sFSR_Indir_FOR_cm
          FD14_SnrDat_sFSL_Indir_FOL_cm
          FD14_SnrDat_sFOR_Indir_FSR_cm
          FD14_SnrDat_sFOR_Indir_FIR_cm
          FD14_SnrDat_sFOL_Indir_FSL_cm
          FD14_SnrDat_sFOL_Indir_FIL_cm
          FD14_SnrDat_sFIR_Indir_FOR_cm
          FD14_SnrDat_sFIR_Indir_FIL_cm
          FD14_SnrDat_sFIL_Indir_FOL_cm
          FD14_SnrDat_sFIL_Indir_FIR_cm
          FD14_SnrDat_RSR_Dir2_cm
          FD14_SnrDat_RSR_Dir1_cm
          FD14_SnrDat_RSL_Dir2_cm
          FD14_SnrDat_RSL_Dir1_cm
          FD14_SnrDat_ROR_Dir2_cm
          FD14_SnrDat_ROR_Dir1_cm
          FD14_SnrDat_ROL_Dir2_cm
          FD14_SnrDat_ROL_Dir1_cm
          FD14_SnrDat_RIR_Dir2_cm
          FD14_SnrDat_RIR_Dir1_cm
          FD14_SnrDat_RIL_Dir2_cm
          FD14_SnrDat_RIL_Dir1_cm
          FD14_SnrDat_FSR_Dir2_cm
          FD14_SnrDat_FSR_Dir1_cm
          FD14_SnrDat_FSL_Dir2_cm
          FD14_SnrDat_FSL_Dir1_cm
          FD14_SnrDat_FOR_Dir2_cm
          FD14_SnrDat_FOR_Dir1_cm
          FD14_SnrDat_FOL_Dir2_cm
          FD14_SnrDat_FOL_Dir1_cm
          FD14_SnrDat_FIR_Dir2_cm
          FD14_SnrDat_FIR_Dir1_cm
          FD14_SnrDat_FIL_Dir2_cm
          FD14_SnrDat_FIL_Dir1_cm
          FD14_slotSide
          FD14_SC_ModuleState_STM_Right
          FD14_SC_ModuleState_STM_Rear
          FD14_SC_ModuleState_STM_Left
          FD14_SC_ModuleState_STM_Front
          FD14_RVCONLY_BTN_PRESSED_b
          FD14_RSR_overTemp_Fault
          FD14_RSR_MinDistance
          FD14_RSR_hardware_Fault
          FD14_RSR_CommUnknown
          FD14_RSR_comm_Fault
          FD14_RSR_Blockage
          FD14_RSL_overTemp_Fault
          FD14_RSL_MinDistance
          FD14_RSL_hardware_Fault
          FD14_RSL_CommUnknown
          FD14_RSL_comm_Fault
          FD14_RSL_Blockage
          FD14_ROR_overTemp_Fault
          FD14_ROR_MinDistance
          FD14_ROR_hardware_Fault
          FD14_ROR_CommUnknown
          FD14_ROR_comm_Fault
          FD14_ROR_Blockage
          FD14_Roll_f32_SC_Right
          FD14_Roll_f32_SC_Rear
          FD14_Roll_f32_SC_Left
          FD14_Roll_f32_SC_Front
          FD14_Roll_f32_OC_Right
          FD14_Roll_f32_OC_Rear
          FD14_Roll_f32_OC_Left
          FD14_Roll_f32_OC_Front
          FD14_Roll_f32_EOL_Right
          FD14_Roll_f32_EOL_Rear
          FD14_Roll_f32_EOL_Left
          FD14_Roll_f32_EOL_Front
          FD14_Roll_f32_Current_Right
          FD14_Roll_f32_Current_Rear
          FD14_ROL_overTemp_Fault
          FD14_ROL_MinDistance
          FD14_ROL_hardware_Fault
          FD14_ROL_CommUnknown
          FD14_ROL_comm_Fault
          FD14_ROL_Blockage
          FD14_RIR_overTemp_Fault
          FD14_RIR_MinDistance
          FD14_RIR_hardware_Fault
          FD14_RIR_CommUnknown
          FD14_RIR_comm_Fault
          FD14_RIR_Blockage
          FD14_RIL_overTemp_Fault
          FD14_RIL_MinDistance
          FD14_RIL_hardware_Fault
          FD14_RIL_CommUnknown
          FD14_RIL_comm_Fault
          FD14_RIL_Blockage
          FD14_RightDoorRearOpen_Icon_b
          FD14_RightDoorRearClose_Icon_b
          FD14_RightDoorFrontOpen_Icon_b
          FD14_RightDoorFrontClose_Icon_b
          FD14_RightCam_NA_b
          FD14_revGear_e
          FD14_Reserved3_b
          FD14_Reserved2_b
          FD14_Reserved13_b
          FD14_Reserved12_b
          FD14_Reserved11_b
          FD14_Reserved10_b
          FD14_Reserved1_b
          FD14_Reserved09_b
          FD14_Reserved08_b
          FD14_Reserved0_b
          FD14_RecognitionInfo
          FD14_RearViewDynamics_b
          FD14_RearCrossButtonSelect_b
          FD14_RearCrossButtonNoSelect_b
          FD14_REAR_TOP_BTN_PRESSED_b
          FD14_REAR_CROSS_BTN_PRESSED_b
          FD14_prndStatus_e
          FD14_Prev_TRG_Stat
          FD14_Prev_SystemState_e
          FD14_Prev_RequestedViewByHmiM_e
          FD14_Prev_DisplayedViewByAcore_e
          FD14_Presentinfo
          FD14_Point_Map_Y_95
          FD14_Point_Map_Y_94
          FD14_Point_Map_Y_93
          FD14_Point_Map_Y_92
          FD14_Point_Map_Y_91
          FD14_Point_Map_Y_90
          FD14_Point_Map_Y_9
          FD14_Point_Map_Y_89
          FD14_Point_Map_Y_88
          FD14_Point_Map_Y_87
          FD14_Point_Map_Y_86
          FD14_Point_Map_Y_85
          FD14_Point_Map_Y_84
          FD14_Point_Map_Y_83
          FD14_Point_Map_Y_82
          FD14_Point_Map_Y_81
          FD14_Point_Map_Y_80
          FD14_Point_Map_Y_8
          FD14_Point_Map_Y_79
          FD14_Point_Map_Y_78
          FD14_Point_Map_Y_77
          FD14_Point_Map_Y_76
          FD14_Point_Map_Y_75
          FD14_Point_Map_Y_74
          FD14_Point_Map_Y_73
          FD14_Point_Map_Y_72
          FD14_Point_Map_Y_71
          FD14_Point_Map_Y_70
          FD14_Point_Map_Y_7
          FD14_Point_Map_Y_69
          FD14_Point_Map_Y_68
          FD14_Point_Map_Y_67
          FD14_Point_Map_Y_66
          FD14_Point_Map_Y_65
          FD14_Point_Map_Y_64
          FD14_Point_Map_Y_63
          FD14_Point_Map_Y_62
          FD14_Point_Map_Y_61
          FD14_Point_Map_Y_60
          FD14_Point_Map_Y_6
          FD14_Point_Map_Y_59
          FD14_Point_Map_Y_58
          FD14_Point_Map_Y_57
          FD14_Point_Map_Y_56
          FD14_Point_Map_Y_55
          FD14_Point_Map_Y_54
          FD14_Point_Map_Y_53
          FD14_Point_Map_Y_52
          FD14_Point_Map_Y_51
          FD14_Point_Map_Y_50
          FD14_Point_Map_Y_5
          FD14_Point_Map_Y_49
          FD14_Point_Map_Y_48
          FD14_Point_Map_Y_47
          FD14_Point_Map_Y_46
          FD14_Point_Map_Y_45
          FD14_Point_Map_Y_44
          FD14_Point_Map_Y_43
          FD14_Point_Map_Y_42
          FD14_Point_Map_Y_41
          FD14_Point_Map_Y_40
          FD14_Point_Map_Y_4
          FD14_Point_Map_Y_39
          FD14_Point_Map_Y_38
          FD14_Point_Map_Y_37
          FD14_Point_Map_Y_36
          FD14_Point_Map_Y_35
          FD14_Point_Map_Y_34
          FD14_Point_Map_Y_33
          FD14_Point_Map_Y_32
          FD14_Point_Map_Y_31
          FD14_Point_Map_Y_30
          FD14_Point_Map_Y_3
          FD14_Point_Map_Y_29
          FD14_Point_Map_Y_28
          FD14_Point_Map_Y_27
          FD14_Point_Map_Y_26
          FD14_Point_Map_Y_25
          FD14_Point_Map_Y_24
          FD14_Point_Map_Y_23
          FD14_Point_Map_Y_22
          FD14_Point_Map_Y_21
          FD14_Point_Map_Y_20
          FD14_Point_Map_Y_2
          FD14_Point_Map_Y_19
          FD14_Point_Map_Y_18
          FD14_Point_Map_Y_17
          FD14_Point_Map_Y_16
          FD14_Point_Map_Y_15
          FD14_Point_Map_Y_14
          FD14_Point_Map_Y_13
          FD14_Point_Map_Y_12
          FD14_Point_Map_Y_11
          FD14_Point_Map_Y_10
          FD14_Point_Map_Y_1
          FD14_Point_Map_Y_0
          FD14_Point_Map_X_95
          FD14_Point_Map_X_94
          FD14_Point_Map_X_93
          FD14_Point_Map_X_92
          FD14_Point_Map_X_91
          FD14_Point_Map_X_90
          FD14_Point_Map_X_9
          FD14_Point_Map_X_89
          FD14_Point_Map_X_88
          FD14_Point_Map_X_87
          FD14_Point_Map_X_86
          FD14_Point_Map_X_85
          FD14_Point_Map_X_84
          FD14_Point_Map_X_83
          FD14_Point_Map_X_82
          FD14_Point_Map_X_81
          FD14_Point_Map_X_80
          FD14_Point_Map_X_8
          FD14_Point_Map_X_79
          FD14_Point_Map_X_78
          FD14_Point_Map_X_77
          FD14_Point_Map_X_76
          FD14_Point_Map_X_75
          FD14_Point_Map_X_74
          FD14_Point_Map_X_73
          FD14_Point_Map_X_72
          FD14_Point_Map_X_71
          FD14_Point_Map_X_70
          FD14_Point_Map_X_7
          FD14_Point_Map_X_69
          FD14_Point_Map_X_68
          FD14_Point_Map_X_67
          FD14_Point_Map_X_66
          FD14_Point_Map_X_65
          FD14_Point_Map_X_64
          FD14_Point_Map_X_63
          FD14_Point_Map_X_62
          FD14_Point_Map_X_61
          FD14_Point_Map_X_60
          FD14_Point_Map_X_6
          FD14_Point_Map_X_59
          FD14_Point_Map_X_58
          FD14_Point_Map_X_57
          FD14_Point_Map_X_56
          FD14_Point_Map_X_55
          FD14_Point_Map_X_54
          FD14_Point_Map_X_53
          FD14_Point_Map_X_52
          FD14_Point_Map_X_51
          FD14_Point_Map_X_50
          FD14_Point_Map_X_5
          FD14_Point_Map_X_49
          FD14_Point_Map_X_48
          FD14_Point_Map_X_47
          FD14_Point_Map_X_46
          FD14_Point_Map_X_45
          FD14_Point_Map_X_44
          FD14_Point_Map_X_43
          FD14_Point_Map_X_42
          FD14_Point_Map_X_41
          FD14_Point_Map_X_40
          FD14_Point_Map_X_4
          FD14_Point_Map_X_39
          FD14_Point_Map_X_38
          FD14_Point_Map_X_37
          FD14_Point_Map_X_36
          FD14_Point_Map_X_35
          FD14_Point_Map_X_34
          FD14_Point_Map_X_33
          FD14_Point_Map_X_32
          FD14_Point_Map_X_31
          FD14_Point_Map_X_30
          FD14_Point_Map_X_3
          FD14_Point_Map_X_29
          FD14_Point_Map_X_28
          FD14_Point_Map_X_27
          FD14_Point_Map_X_26
          FD14_Point_Map_X_25
          FD14_Point_Map_X_24
          FD14_Point_Map_X_23
          FD14_Point_Map_X_22
          FD14_Point_Map_X_21
          FD14_Point_Map_X_20
          FD14_Point_Map_X_2
          FD14_Point_Map_X_19
          FD14_Point_Map_X_18
          FD14_Point_Map_X_17
          FD14_Point_Map_X_16
          FD14_Point_Map_X_15
          FD14_Point_Map_X_14
          FD14_Point_Map_X_13
          FD14_Point_Map_X_12
          FD14_Point_Map_X_11
          FD14_Point_Map_X_10
          FD14_Point_Map_X_1
          FD14_Point_Map_X_0
          FD14_Point_Map_Reserved_95
          FD14_Point_Map_Reserved_94
          FD14_Point_Map_Reserved_93
          FD14_Point_Map_Reserved_92
          FD14_Point_Map_Reserved_91
          FD14_Point_Map_Reserved_90
          FD14_Point_Map_Reserved_9
          FD14_Point_Map_Reserved_89
          FD14_Point_Map_Reserved_88
          FD14_Point_Map_Reserved_87
          FD14_Point_Map_Reserved_86
          FD14_Point_Map_Reserved_85
          FD14_Point_Map_Reserved_84
          FD14_Point_Map_Reserved_83
          FD14_Point_Map_Reserved_82
          FD14_Point_Map_Reserved_81
          FD14_Point_Map_Reserved_80
          FD14_Point_Map_Reserved_8
          FD14_Point_Map_Reserved_79
          FD14_Point_Map_Reserved_78
          FD14_Point_Map_Reserved_77
          FD14_Point_Map_Reserved_76
          FD14_Point_Map_Reserved_75
          FD14_Point_Map_Reserved_74
          FD14_Point_Map_Reserved_73
          FD14_Point_Map_Reserved_72
          FD14_Point_Map_Reserved_71
          FD14_Point_Map_Reserved_70
          FD14_Point_Map_Reserved_7
          FD14_Point_Map_Reserved_69
          FD14_Point_Map_Reserved_68
          FD14_Point_Map_Reserved_67
          FD14_Point_Map_Reserved_66
          FD14_Point_Map_Reserved_65
          FD14_Point_Map_Reserved_64
          FD14_Point_Map_Reserved_63
          FD14_Point_Map_Reserved_62
          FD14_Point_Map_Reserved_61
          FD14_Point_Map_Reserved_60
          FD14_Point_Map_Reserved_6
          FD14_Point_Map_Reserved_59
          FD14_Point_Map_Reserved_58
          FD14_Point_Map_Reserved_57
          FD14_Point_Map_Reserved_56
          FD14_Point_Map_Reserved_55
          FD14_Point_Map_Reserved_54
          FD14_Point_Map_Reserved_53
          FD14_Point_Map_Reserved_52
          FD14_Point_Map_Reserved_51
          FD14_Point_Map_Reserved_50
          FD14_Point_Map_Reserved_5
          FD14_Point_Map_Reserved_49
          FD14_Point_Map_Reserved_48
          FD14_Point_Map_Reserved_47
          FD14_Point_Map_Reserved_46
          FD14_Point_Map_Reserved_45
          FD14_Point_Map_Reserved_44
          FD14_Point_Map_Reserved_43
          FD14_Point_Map_Reserved_42
          FD14_Point_Map_Reserved_41
          FD14_Point_Map_Reserved_40
          FD14_Point_Map_Reserved_4
          FD14_Point_Map_Reserved_39
          FD14_Point_Map_Reserved_38
          FD14_Point_Map_Reserved_37
          FD14_Point_Map_Reserved_36
          FD14_Point_Map_Reserved_35
          FD14_Point_Map_Reserved_34
          FD14_Point_Map_Reserved_33
          FD14_Point_Map_Reserved_32
          FD14_Point_Map_Reserved_31
          FD14_Point_Map_Reserved_30
          FD14_Point_Map_Reserved_3
          FD14_Point_Map_Reserved_29
          FD14_Point_Map_Reserved_28
          FD14_Point_Map_Reserved_27
          FD14_Point_Map_Reserved_26
          FD14_Point_Map_Reserved_25
          FD14_Point_Map_Reserved_24
          FD14_Point_Map_Reserved_23
          FD14_Point_Map_Reserved_22
          FD14_Point_Map_Reserved_21
          FD14_Point_Map_Reserved_20
          FD14_Point_Map_Reserved_2
          FD14_Point_Map_Reserved_19
          FD14_Point_Map_Reserved_18
          FD14_Point_Map_Reserved_17
          FD14_Point_Map_Reserved_16
          FD14_Point_Map_Reserved_15
          FD14_Point_Map_Reserved_14
          FD14_Point_Map_Reserved_13
          FD14_Point_Map_Reserved_12
          FD14_Point_Map_Reserved_11
          FD14_Point_Map_Reserved_10
          FD14_Point_Map_Reserved_1
          FD14_Point_Map_Reserved_0
          FD14_Point_Map_Height_95
          FD14_Point_Map_Height_94
          FD14_Point_Map_Height_93
          FD14_Point_Map_Height_92
          FD14_Point_Map_Height_91
          FD14_Point_Map_Height_90
          FD14_Point_Map_Height_9
          FD14_Point_Map_Height_89
          FD14_Point_Map_Height_88
          FD14_Point_Map_Height_87
          FD14_Point_Map_Height_86
          FD14_Point_Map_Height_85
          FD14_Point_Map_Height_84
          FD14_Point_Map_Height_83
          FD14_Point_Map_Height_82
          FD14_Point_Map_Height_81
          FD14_Point_Map_Height_80
          FD14_Point_Map_Height_8
          FD14_Point_Map_Height_79
          FD14_Point_Map_Height_78
          FD14_Point_Map_Height_77
          FD14_Point_Map_Height_76
          FD14_Point_Map_Height_75
          FD14_Point_Map_Height_74
          FD14_Point_Map_Height_73
          FD14_Point_Map_Height_72
          FD14_Point_Map_Height_71
          FD14_Point_Map_Height_70
          FD14_Point_Map_Height_7
          FD14_Point_Map_Height_69
          FD14_Point_Map_Height_68
          FD14_Point_Map_Height_67
          FD14_Point_Map_Height_66
          FD14_Point_Map_Height_65
          FD14_Point_Map_Height_64
          FD14_Point_Map_Height_63
          FD14_Point_Map_Height_62
          FD14_Point_Map_Height_61
          FD14_Point_Map_Height_60
          FD14_Point_Map_Height_6
          FD14_Point_Map_Height_59
          FD14_Point_Map_Height_58
          FD14_Point_Map_Height_57
          FD14_Point_Map_Height_56
          FD14_Point_Map_Height_55
          FD14_Point_Map_Height_54
          FD14_Point_Map_Height_53
          FD14_Point_Map_Height_52
          FD14_Point_Map_Height_51
          FD14_Point_Map_Height_50
          FD14_Point_Map_Height_5
          FD14_Point_Map_Height_49
          FD14_Point_Map_Height_48
          FD14_Point_Map_Height_47
          FD14_Point_Map_Height_46
          FD14_Point_Map_Height_45
          FD14_Point_Map_Height_44
          FD14_Point_Map_Height_43
          FD14_Point_Map_Height_42
          FD14_Point_Map_Height_41
          FD14_Point_Map_Height_40
          FD14_Point_Map_Height_4
          FD14_Point_Map_Height_39
          FD14_Point_Map_Height_38
          FD14_Point_Map_Height_37
          FD14_Point_Map_Height_36
          FD14_Point_Map_Height_35
          FD14_Point_Map_Height_34
          FD14_Point_Map_Height_33
          FD14_Point_Map_Height_32
          FD14_Point_Map_Height_31
          FD14_Point_Map_Height_30
          FD14_Point_Map_Height_3
          FD14_Point_Map_Height_29
          FD14_Point_Map_Height_28
          FD14_Point_Map_Height_27
          FD14_Point_Map_Height_26
          FD14_Point_Map_Height_25
          FD14_Point_Map_Height_24
          FD14_Point_Map_Height_23
          FD14_Point_Map_Height_22
          FD14_Point_Map_Height_21
          FD14_Point_Map_Height_20
          FD14_Point_Map_Height_2
          FD14_Point_Map_Height_19
          FD14_Point_Map_Height_18
          FD14_Point_Map_Height_17
          FD14_Point_Map_Height_16
          FD14_Point_Map_Height_15
          FD14_Point_Map_Height_14
          FD14_Point_Map_Height_13
          FD14_Point_Map_Height_12
          FD14_Point_Map_Height_11
          FD14_Point_Map_Height_10
          FD14_Point_Map_Height_1
          FD14_Point_Map_Height_0
          FD14_Point_Map_Cruising_Age_95
          FD14_Point_Map_Cruising_Age_94
          FD14_Point_Map_Cruising_Age_93
          FD14_Point_Map_Cruising_Age_92
          FD14_Point_Map_Cruising_Age_91
          FD14_Point_Map_Cruising_Age_90
          FD14_Point_Map_Cruising_Age_9
          FD14_Point_Map_Cruising_Age_89
          FD14_Point_Map_Cruising_Age_88
          FD14_Point_Map_Cruising_Age_87
          FD14_Point_Map_Cruising_Age_86
          FD14_Point_Map_Cruising_Age_85
          FD14_Point_Map_Cruising_Age_84
          FD14_Point_Map_Cruising_Age_83
          FD14_Point_Map_Cruising_Age_82
          FD14_Point_Map_Cruising_Age_81
          FD14_Point_Map_Cruising_Age_80
          FD14_Point_Map_Cruising_Age_8
          FD14_Point_Map_Cruising_Age_79
          FD14_Point_Map_Cruising_Age_78
          FD14_Point_Map_Cruising_Age_77
          FD14_Point_Map_Cruising_Age_76
          FD14_Point_Map_Cruising_Age_75
          FD14_Point_Map_Cruising_Age_74
          FD14_Point_Map_Cruising_Age_73
          FD14_Point_Map_Cruising_Age_72
          FD14_Point_Map_Cruising_Age_71
          FD14_Point_Map_Cruising_Age_70
          FD14_Point_Map_Cruising_Age_7
          FD14_Point_Map_Cruising_Age_69
          FD14_Point_Map_Cruising_Age_68
          FD14_Point_Map_Cruising_Age_67
          FD14_Point_Map_Cruising_Age_66
          FD14_Point_Map_Cruising_Age_65
          FD14_Point_Map_Cruising_Age_64
          FD14_Point_Map_Cruising_Age_63
          FD14_Point_Map_Cruising_Age_62
          FD14_Point_Map_Cruising_Age_61
          FD14_Point_Map_Cruising_Age_60
          FD14_Point_Map_Cruising_Age_6
          FD14_Point_Map_Cruising_Age_59
          FD14_Point_Map_Cruising_Age_58
          FD14_Point_Map_Cruising_Age_57
          FD14_Point_Map_Cruising_Age_56
          FD14_Point_Map_Cruising_Age_55
          FD14_Point_Map_Cruising_Age_54
          FD14_Point_Map_Cruising_Age_53
          FD14_Point_Map_Cruising_Age_52
          FD14_Point_Map_Cruising_Age_51
          FD14_Point_Map_Cruising_Age_50
          FD14_Point_Map_Cruising_Age_5
          FD14_Point_Map_Cruising_Age_49
          FD14_Point_Map_Cruising_Age_48
          FD14_Point_Map_Cruising_Age_47
          FD14_Point_Map_Cruising_Age_46
          FD14_Point_Map_Cruising_Age_45
          FD14_Point_Map_Cruising_Age_44
          FD14_Point_Map_Cruising_Age_43
          FD14_Point_Map_Cruising_Age_42
          FD14_Point_Map_Cruising_Age_41
          FD14_Point_Map_Cruising_Age_40
          FD14_Point_Map_Cruising_Age_4
          FD14_Point_Map_Cruising_Age_39
          FD14_Point_Map_Cruising_Age_38
          FD14_Point_Map_Cruising_Age_37
          FD14_Point_Map_Cruising_Age_36
          FD14_Point_Map_Cruising_Age_35
          FD14_Point_Map_Cruising_Age_34
          FD14_Point_Map_Cruising_Age_33
          FD14_Point_Map_Cruising_Age_32
          FD14_Point_Map_Cruising_Age_31
          FD14_Point_Map_Cruising_Age_30
          FD14_Point_Map_Cruising_Age_3
          FD14_Point_Map_Cruising_Age_29
          FD14_Point_Map_Cruising_Age_28
          FD14_Point_Map_Cruising_Age_27
          FD14_Point_Map_Cruising_Age_26
          FD14_Point_Map_Cruising_Age_25
          FD14_Point_Map_Cruising_Age_24
          FD14_Point_Map_Cruising_Age_23
          FD14_Point_Map_Cruising_Age_22
          FD14_Point_Map_Cruising_Age_21
          FD14_Point_Map_Cruising_Age_20
          FD14_Point_Map_Cruising_Age_2
          FD14_Point_Map_Cruising_Age_19
          FD14_Point_Map_Cruising_Age_18
          FD14_Point_Map_Cruising_Age_17
          FD14_Point_Map_Cruising_Age_16
          FD14_Point_Map_Cruising_Age_15
          FD14_Point_Map_Cruising_Age_14
          FD14_Point_Map_Cruising_Age_13
          FD14_Point_Map_Cruising_Age_12
          FD14_Point_Map_Cruising_Age_11
          FD14_Point_Map_Cruising_Age_10
          FD14_Point_Map_Cruising_Age_1
          FD14_Point_Map_Cruising_Age_0
          FD14_Point_Map_Confidence_95
          FD14_Point_Map_Confidence_94
          FD14_Point_Map_Confidence_93
          FD14_Point_Map_Confidence_92
          FD14_Point_Map_Confidence_91
          FD14_Point_Map_Confidence_90
          FD14_Point_Map_Confidence_9
          FD14_Point_Map_Confidence_89
          FD14_Point_Map_Confidence_88
          FD14_Point_Map_Confidence_87
          FD14_Point_Map_Confidence_86
          FD14_Point_Map_Confidence_85
          FD14_Point_Map_Confidence_84
          FD14_Point_Map_Confidence_83
          FD14_Point_Map_Confidence_82
          FD14_Point_Map_Confidence_81
          FD14_Point_Map_Confidence_80
          FD14_Point_Map_Confidence_8
          FD14_Point_Map_Confidence_79
          FD14_Point_Map_Confidence_78
          FD14_Point_Map_Confidence_77
          FD14_Point_Map_Confidence_76
          FD14_Point_Map_Confidence_75
          FD14_Point_Map_Confidence_74
          FD14_Point_Map_Confidence_73
          FD14_Point_Map_Confidence_72
          FD14_Point_Map_Confidence_71
          FD14_Point_Map_Confidence_70
          FD14_Point_Map_Confidence_7
          FD14_Point_Map_Confidence_69
          FD14_Point_Map_Confidence_68
          FD14_Point_Map_Confidence_67
          FD14_Point_Map_Confidence_66
          FD14_Point_Map_Confidence_65
          FD14_Point_Map_Confidence_64
          FD14_Point_Map_Confidence_63
          FD14_Point_Map_Confidence_62
          FD14_Point_Map_Confidence_61
          FD14_Point_Map_Confidence_60
          FD14_Point_Map_Confidence_6
          FD14_Point_Map_Confidence_59
          FD14_Point_Map_Confidence_58
          FD14_Point_Map_Confidence_57
          FD14_Point_Map_Confidence_56
          FD14_Point_Map_Confidence_55
          FD14_Point_Map_Confidence_54
          FD14_Point_Map_Confidence_53
          FD14_Point_Map_Confidence_52
          FD14_Point_Map_Confidence_51
          FD14_Point_Map_Confidence_50
          FD14_Point_Map_Confidence_5
          FD14_Point_Map_Confidence_49
          FD14_Point_Map_Confidence_48
          FD14_Point_Map_Confidence_47
          FD14_Point_Map_Confidence_46
          FD14_Point_Map_Confidence_45
          FD14_Point_Map_Confidence_44
          FD14_Point_Map_Confidence_43
          FD14_Point_Map_Confidence_42
          FD14_Point_Map_Confidence_41
          FD14_Point_Map_Confidence_40
          FD14_Point_Map_Confidence_4
          FD14_Point_Map_Confidence_39
          FD14_Point_Map_Confidence_38
          FD14_Point_Map_Confidence_37
          FD14_Point_Map_Confidence_36
          FD14_Point_Map_Confidence_35
          FD14_Point_Map_Confidence_34
          FD14_Point_Map_Confidence_33
          FD14_Point_Map_Confidence_32
          FD14_Point_Map_Confidence_31
          FD14_Point_Map_Confidence_30
          FD14_Point_Map_Confidence_3
          FD14_Point_Map_Confidence_29
          FD14_Point_Map_Confidence_28
          FD14_Point_Map_Confidence_27
          FD14_Point_Map_Confidence_26
          FD14_Point_Map_Confidence_25
          FD14_Point_Map_Confidence_24
          FD14_Point_Map_Confidence_23
          FD14_Point_Map_Confidence_22
          FD14_Point_Map_Confidence_21
          FD14_Point_Map_Confidence_20
          FD14_Point_Map_Confidence_2
          FD14_Point_Map_Confidence_19
          FD14_Point_Map_Confidence_18
          FD14_Point_Map_Confidence_17
          FD14_Point_Map_Confidence_16
          FD14_Point_Map_Confidence_15
          FD14_Point_Map_Confidence_14
          FD14_Point_Map_Confidence_13
          FD14_Point_Map_Confidence_12
          FD14_Point_Map_Confidence_11
          FD14_Point_Map_Confidence_10
          FD14_Point_Map_Confidence_1
          FD14_Point_Map_Confidence_0
          FD14_Point_Map_Age_95
          FD14_Point_Map_Age_94
          FD14_Point_Map_Age_93
          FD14_Point_Map_Age_92
          FD14_Point_Map_Age_91
          FD14_Point_Map_Age_90
          FD14_Point_Map_Age_9
          FD14_Point_Map_Age_89
          FD14_Point_Map_Age_88
          FD14_Point_Map_Age_87
          FD14_Point_Map_Age_86
          FD14_Point_Map_Age_85
          FD14_Point_Map_Age_84
          FD14_Point_Map_Age_83
          FD14_Point_Map_Age_82
          FD14_Point_Map_Age_81
          FD14_Point_Map_Age_80
          FD14_Point_Map_Age_8
          FD14_Point_Map_Age_79
          FD14_Point_Map_Age_78
          FD14_Point_Map_Age_77
          FD14_Point_Map_Age_76
          FD14_Point_Map_Age_75
          FD14_Point_Map_Age_74
          FD14_Point_Map_Age_73
          FD14_Point_Map_Age_72
          FD14_Point_Map_Age_71
          FD14_Point_Map_Age_70
          FD14_Point_Map_Age_7
          FD14_Point_Map_Age_69
          FD14_Point_Map_Age_68
          FD14_Point_Map_Age_67
          FD14_Point_Map_Age_66
          FD14_Point_Map_Age_65
          FD14_Point_Map_Age_64
          FD14_Point_Map_Age_63
          FD14_Point_Map_Age_62
          FD14_Point_Map_Age_61
          FD14_Point_Map_Age_60
          FD14_Point_Map_Age_6
          FD14_Point_Map_Age_59
          FD14_Point_Map_Age_58
          FD14_Point_Map_Age_57
          FD14_Point_Map_Age_56
          FD14_Point_Map_Age_55
          FD14_Point_Map_Age_54
          FD14_Point_Map_Age_53
          FD14_Point_Map_Age_52
          FD14_Point_Map_Age_51
          FD14_Point_Map_Age_50
          FD14_Point_Map_Age_5
          FD14_Point_Map_Age_49
          FD14_Point_Map_Age_48
          FD14_Point_Map_Age_47
          FD14_Point_Map_Age_46
          FD14_Point_Map_Age_45
          FD14_Point_Map_Age_44
          FD14_Point_Map_Age_43
          FD14_Point_Map_Age_42
          FD14_Point_Map_Age_41
          FD14_Point_Map_Age_40
          FD14_Point_Map_Age_4
          FD14_Point_Map_Age_39
          FD14_Point_Map_Age_38
          FD14_Point_Map_Age_37
          FD14_Point_Map_Age_36
          FD14_Point_Map_Age_35
          FD14_Point_Map_Age_34
          FD14_Point_Map_Age_33
          FD14_Point_Map_Age_32
          FD14_Point_Map_Age_31
          FD14_Point_Map_Age_30
          FD14_Point_Map_Age_3
          FD14_Point_Map_Age_29
          FD14_Point_Map_Age_28
          FD14_Point_Map_Age_27
          FD14_Point_Map_Age_26
          FD14_Point_Map_Age_25
          FD14_Point_Map_Age_24
          FD14_Point_Map_Age_23
          FD14_Point_Map_Age_22
          FD14_Point_Map_Age_21
          FD14_Point_Map_Age_20
          FD14_Point_Map_Age_2
          FD14_Point_Map_Age_19
          FD14_Point_Map_Age_18
          FD14_Point_Map_Age_17
          FD14_Point_Map_Age_16
          FD14_Point_Map_Age_15
          FD14_Point_Map_Age_14
          FD14_Point_Map_Age_13
          FD14_Point_Map_Age_12
          FD14_Point_Map_Age_11
          FD14_Point_Map_Age_10
          FD14_Point_Map_Age_1
          FD14_Point_Map_Age_0
          FD14_Pntdebugdata_3
          FD14_Pntdebugdata_2
          FD14_Pntdebugdata_1
          FD14_Pntdebugdata_0
          FD14_Pitch_f32_SC_Right
          FD14_Pitch_f32_SC_Rear
          FD14_Pitch_f32_SC_Left
          FD14_Pitch_f32_SC_Front
          FD14_Pitch_f32_OC_Right
          FD14_Pitch_f32_OC_Rear
          FD14_Pitch_f32_OC_Left
          FD14_Pitch_f32_OC_Front
          FD14_Pitch_f32_EOL_Right
          FD14_Pitch_f32_EOL_Rear
          FD14_Pitch_f32_EOL_Left
          FD14_Pitch_f32_EOL_Front
          FD14_Pitch_f32_Current_Right
          FD14_Pitch_f32_Current_Rear
          FD14_perpParkDirectionSel
          FD14_PDC_RearRight_Yellow_b
          FD14_PDC_RearRight_Red_b
          FD14_PDC_RearLeft_Yellow_b
          FD14_PDC_RearLeft_Red_b
          FD14_PDC_RearCenter_Yellow_b
          FD14_PDC_RearCenter_Red_b
          FD14_PDC_FrontRight_Yellow_b
          FD14_PDC_FrontRight_Red_b
          FD14_PDC_FrontLeft_Yellow_b
          FD14_PDC_FrontLeft_Red_b
          FD14_PDC_FrontCenter_Yellow_b
          FD14_PDC_FrontCenter_Red_b
          FD14_parkingSlotType
          FD14_parkingDirection
          FD14_parkExtSideSel
          FD14_OFFROAD_PRSNT_MC_BTN_PRESSED_b
          FD14_OFFROAD_ABSNT_MC_BTN_PRESSED_b
          FD14_OFFRD_PRSNT_AUXCAM_BTN_PRESSED_b
          FD14_OFFRD_ABSNT_AUXCAM_BTN_PRESSED_b
          FD14_OC_ModuleState_STM_Right
          FD14_OC_ModuleState_STM_Rear
          FD14_OC_ModuleState_STM_Left
          FD14_OC_ModuleState_STM_Front
          FD14_OBTLRecalibrate
          FD14_objConf_e
          FD14_obj_Pos_Longi
          FD14_obj_Pos_Lat
          FD14_NFCD_ObjValid_9
          FD14_NFCD_ObjValid_8
          FD14_NFCD_ObjValid_7
          FD14_NFCD_ObjValid_6
          FD14_NFCD_ObjValid_5
          FD14_NFCD_ObjValid_4
          FD14_NFCD_ObjValid_3
          FD14_NFCD_ObjValid_2
          FD14_NFCD_ObjValid_1
          FD14_NFCD_ObjValid_0
          FD14_NFCD_DistanceToClosestPoint_1_9
          FD14_NFCD_DistanceToClosestPoint_1_8
          FD14_NFCD_DistanceToClosestPoint_1_7
          FD14_NFCD_DistanceToClosestPoint_1_6
          FD14_NFCD_DistanceToClosestPoint_1_5
          FD14_NFCD_DistanceToClosestPoint_1_4
          FD14_NFCD_DistanceToClosestPoint_1_3
          FD14_NFCD_DistanceToClosestPoint_1_2
          FD14_NFCD_DistanceToClosestPoint_1_1
          FD14_NFCD_DistanceToClosestPoint_1_0
          FD14_NFCD_DistanceToClosestPoint_0_9
          FD14_NFCD_DistanceToClosestPoint_0_8
          FD14_NFCD_DistanceToClosestPoint_0_7
          FD14_NFCD_DistanceToClosestPoint_0_6
          FD14_NFCD_DistanceToClosestPoint_0_5
          FD14_NFCD_DistanceToClosestPoint_0_4
          FD14_NFCD_DistanceToClosestPoint_0_3
          FD14_NFCD_DistanceToClosestPoint_0_2
          FD14_NFCD_DistanceToClosestPoint_0_1
          FD14_NFCD_DistanceToClosestPoint_0_0
          FD14_NetCfg_TRSCM_e
          FD14_msgcntrCvpamFdData1_u8
          FD14_MOT_ObjVelY_9
          FD14_MOT_ObjVelY_8
          FD14_MOT_ObjVelY_7
          FD14_MOT_ObjVelY_6
          FD14_MOT_ObjVelY_5
          FD14_MOT_ObjVelY_4
          FD14_MOT_ObjVelY_3
          FD14_MOT_ObjVelY_2
          FD14_MOT_ObjVelY_1
          FD14_MOT_ObjVelY_0
          FD14_MOT_ObjVelX_9
          FD14_MOT_ObjVelX_8
          FD14_MOT_ObjVelX_7
          FD14_MOT_ObjVelX_6
          FD14_MOT_ObjVelX_5
          FD14_MOT_ObjVelX_4
          FD14_MOT_ObjVelX_3
          FD14_MOT_ObjVelX_2
          FD14_MOT_ObjVelX_1
          FD14_MOT_ObjVelX_0
          FD14_MOT_ObjValid_9
          FD14_MOT_ObjValid_8
          FD14_MOT_ObjValid_7
          FD14_MOT_ObjValid_6
          FD14_MOT_ObjValid_5
          FD14_MOT_ObjValid_4
          FD14_MOT_ObjValid_3
          FD14_MOT_ObjValid_2
          FD14_MOT_ObjValid_1
          FD14_MOT_ObjValid_0
          FD14_MOT_ObjectDimensions_1_9
          FD14_MOT_ObjectDimensions_1_8
          FD14_MOT_ObjectDimensions_1_7
          FD14_MOT_ObjectDimensions_1_6
          FD14_MOT_ObjectDimensions_1_5
          FD14_MOT_ObjectDimensions_1_4
          FD14_MOT_ObjectDimensions_1_3
          FD14_MOT_ObjectDimensions_1_2
          FD14_MOT_ObjectDimensions_1_1
          FD14_MOT_ObjectDimensions_1_0
          FD14_MOT_ObjectDimensions_0_9
          FD14_MOT_ObjectDimensions_0_8
          FD14_MOT_ObjectDimensions_0_7
          FD14_MOT_ObjectDimensions_0_6
          FD14_MOT_ObjectDimensions_0_5
          FD14_MOT_ObjectDimensions_0_4
          FD14_MOT_ObjectDimensions_0_3
          FD14_MOT_ObjectDimensions_0_2
          FD14_MOT_ObjectDimensions_0_1
          FD14_MOT_ObjectDimensions_0_0
          FD14_MOT_ClosestPntDist_1_9
          FD14_MOT_ClosestPntDist_1_8
          FD14_MOT_ClosestPntDist_1_7
          FD14_MOT_ClosestPntDist_1_6
          FD14_MOT_ClosestPntDist_1_5
          FD14_MOT_ClosestPntDist_1_4
          FD14_MOT_ClosestPntDist_1_3
          FD14_MOT_ClosestPntDist_1_2
          FD14_MOT_ClosestPntDist_1_1
          FD14_MOT_ClosestPntDist_1_0
          FD14_MOT_ClosestPntDist_0_9
          FD14_MOT_ClosestPntDist_0_8
          FD14_MOT_ClosestPntDist_0_7
          FD14_MOT_ClosestPntDist_0_6
          FD14_MOT_ClosestPntDist_0_5
          FD14_MOT_ClosestPntDist_0_4
          FD14_MOT_ClosestPntDist_0_3
          FD14_MOT_ClosestPntDist_0_2
          FD14_MOT_ClosestPntDist_0_1
          FD14_MOT_ClosestPntDist_0_0
          FD14_MoreCamsIconFullScreenNoSelect_b
          FD14_MoreCamsButton2Select_b
          FD14_MoreCamsButton2NoSelect_b
          FD14_MoreCamsButton1Select_b
          FD14_MoreCamsButton1NoSelect_b
          FD14_MinDistance_TimeStamp
          FD14_MeTRSC_m_TrailerBeamLen
          FD14_MeTRSC_M_SteeringTorqInfo
          FD14_MeTRSC_m_HitchLength
          FD14_MeTRSC_m_DetTrailerBeamLen
          FD14_MeTRSC_e_TurnAroundSubState
          FD14_MeTRSC_e_TRSCStat
          FD14_MeTRSC_e_TrlrRecogInfo
          FD14_MeTRSC_e_TrlrPrsntInfoCAN
          FD14_MeTRSC_e_TrlrPrsntInfo
          FD14_MeTRSC_e_TrlrCalInfo
          FD14_MeTRSC_e_TrlrAngSign
          FD14_MeTRSC_e_TrailerID
          FD14_MeTRSC_e_TADState
          FD14_MeTRSC_e_TADCalibrationSubstate
          FD14_MeTRSC_e_CalFail
          FD14_MeTRSC_deg_TADAngleRate
          FD14_MeTRSC_deg_TADAngle
          FD14_MeTRSC_deg_MaxAllowedTADAngle
          FD14_MeTRSC_deg_KnobAngle
          FD14_MeTRSC_deg_JackknifeThrAngle
          FD14_MeTRSC_deg_JackKnifeAngle
          FD14_MeTRSC_deg_DetJackknifeThrAngle
          FD14_MeTRSC_deg_DetJackKnifeAngle
          FD14_MeTRSC_cnt_TrlrCalibFailCntInfo
          FD14_MeTRSC_b_TRSCSwitchPressed
          FD14_MeTRSC_b_TrlrRevSteeringStsInfo
          FD14_MeTRSC_b_TrlrCalibPopInfo
          FD14_MeTRSC_b_TrlrCalibDelayInfo
          FD14_MeTRSC_b_OBTLRecalibrate
          FD14_MeTRSC_b_MoreCamSoftButtEnbl
          FD14_MeTHA_px_HitchPntY
          FD14_MeTHA_px_HitchPntX
          FD14_MeTHA_px_HitchCplrPixDiffLong
          FD14_MeTHA_px_HitchCplrPixDiffLat
          FD14_MeTHA_px_CplrPntY
          FD14_MeTHA_px_CplrPntX
          FD14_MeTHA_pct_CplrTrckConf
          FD14_MeTHA_pct_CplrDetConf
          FD14_MeTHA_e_THAStateInfo
          FD14_MeTHA_e_ScreenRequest
          FD14_MeTHA_e_RearBrkSupprInfo
          FD14_MeTHA_e_HitchDetctStatus
          FD14_MeTHA_e_CplrDetctStatus
          FD14_MeTHA_deg_RoadWhlAng
          FD14_MeTHA_deg_CplrAng
          FD14_MeTHA_b_UsrHitchCnfm
          FD14_MeTHA_b_UsrCplrSelCnfm
          FD14_MeTHA_b_TrlrCplrStatus
          FD14_MeTHA_b_THAAbortStatus
          FD14_MeTHA_b_EnblRearParkAsstTrg
          FD14_MeSVS_e_DispView2Info
          FD14_MeSVS_b_MoreCamReqSts
          FD14_MePRX_e_Wheelbase
          FD14_MePRX_e_VehLineCfg
          FD14_MePRX_e_VariantID
          FD14_MePRX_e_SteerRatRackPinionType
          FD14_MePRX_e_RadDispType
          FD14_MePRX_e_PAMTunSet
          FD14_MePRX_e_MirrorType
          FD14_MePRX_e_AutonomyLvl
          FD14_MePRX_b_TRSCPresence
          FD14_MePRX_b_TRGPresence
          FD14_MePRX_b_SurroundViewCamera
          FD14_MePRX_b_FrwFacingCam
          FD14_MePRX_b_CANNode95
          FD14_MePRX_b_CanNode27
          FD14_MePRX_b_AuxTrlrCam
          FD14_MeAP_e_PP_state
          FD14_MeAP_e_ParkAssistStatus
          FD14_MeAP_e_Park_state
          FD14_MeAP_deg_StrCmd
          FD14_MeAP_cnt_TransDebugVar_Copy_1
          FD14_MeAP_cnt_TransDebugVar
          FD14_MeAP_cnt_StateDebugVar
          FD14_MeAP_cm_RearRightMinXDist
          FD14_MeAP_cm_RearLeftMinXDist
          FD14_MeAP_cm_RearCenterMinXDist
          FD14_MeAP_cm_FrntRightMinXDist
          FD14_MeAP_cm_FrntLeftMinXDist
          FD14_MeAP_cm_FrntCenterMinXDist
          FD14_MeAP_b_VehCndSts
          FD14_MeAP_b_VCOpPaused
          FD14_MeAP_b_SteerActionReq
          FD14_MeAP_b_StandStill
          FD14_MeAP_b_SeekSpdExceedTimeout
          FD14_MeAP_b_RPAwithBrkStatus
          FD14_MeAP_b_RPAVolDefMed
          FD14_MeAP_b_RPAStatus
          FD14_MeAP_b_RPADisable
          FD14_MeAP_b_RPAActvTrlr
          FD14_MeAP_b_PPPADisable
          FD14_MeAP_b_PPPADefEng
          FD14_MeAP_b_PPPAActvTrlr
          FD14_MeAP_b_PPPAActv4LOW
          FD14_MeAP_b_PosMet
          FD14_MeAP_b_PAVolDefMed
          FD14_MeAP_b_PausedPressBtnTimeout
          FD14_MeAP_b_PARBDisable
          FD14_MeAP_b_PARBActvTrlr
          FD14_MeAP_b_PARBActv4LOW
          FD14_MeAP_b_ObjInPathTimeout
          FD14_MeAP_b_ManeuverSuccess
          FD14_MeAP_b_ManeuverAbort
          FD14_MeAP_b_GearShiftWaitTimeout
          FD14_MeAP_b_FPAVolDefMed
          FD14_MeAP_b_FPAStatus
          FD14_MeAP_b_FPADisable
          FD14_MeAP_b_FeatureEnbl
          FD14_MeAP_b_EPSInterfaceTimeout
          FD14_MeAP_b_DriverOverride
          FD14_MeAP_b_CamHandshakeTimeout
          FD14_MeAP_b_BSMInterfaceTimeout
          FD14_MeAP_b_BSMHandshakeActv
          FD14_MeAP_b_APInitSts
          FD14_MeAP_a_ThrtlCmd
          FD14_MeAP_a_BrkCmd
          FD14_MaxTadAngle
          FD14_MAGNIFIER_BTN_PRESSED_b
          FD14_macCvpamFdData1_u64
          FD14_MaAP_m_ParkSpot4RearStreetY
          FD14_MaAP_m_ParkSpot4RearStreetX
          FD14_MaAP_m_ParkSpot3RearBorderY
          FD14_MaAP_m_ParkSpot3RearBorderX
          FD14_MaAP_m_ParkSpot2FrntBorderY
          FD14_MaAP_m_ParkSpot2FrntBorderX
          FD14_MaAP_m_ParkSpot1FrntStreetY
          FD14_MaAP_m_ParkSpot1FrntStreetX
          FD14_M_VIEW_ZOOM_STS_b
          FD14_M_VIEW_SCRN_TCH_STS_b
          FD14_M_THA_SFT_BTN_PRESSED_b
          FD14_M_START_BTN_PRESSED_b
          FD14_M_Requested_THA_State
          FD14_m_QM_FID_TRSC_LIMITED_View
          FD14_m_QM_FID_TRSC_LIMITED_DefView
          FD14_m_QM_FID_TRSC_DISABLED
          FD14_m_QM_FID_TRSC_CAM_CAL_ABORT
          FD14_m_QM_FID_TRSC_ASCMDef
          FD14_M_Progress_Bar_Percentage
          FD14_M_Progress_Bar_Distance
          FD14_M_Maneuver_Initial_Run
          FD14_m_FPAToNVMWriteNVMParam_b
          FD14_m_FPAToNVMReadNVMParam_b
          FD14_m_FPAToNVMParkInStyle
          FD14_m_FpaInfoToVCParkOutStyle
          FD14_m_FPAInfoToUSSOMSlotID
          FD14_m_FPAInfoToPLDSlotID
          FD14_M_FFClatch_e
          FD14_M_Current_THA_State_On_Zync
          FD14_M_Current_THA_State_On_Screen
          FD14_M_CPLR_POS_Y_u
          FD14_M_CPLR_POS_X_u
          FD14_M_Cplr_Htch_Distance
          FD14_M_CONFIRM_BTN_PRESSED_b
          FD14_M_BURV_Memory_e
          FD14_lrwsST_e
          FD14_Log_SnrMeasData_7
          FD14_Log_SnrMeasData_6
          FD14_Log_SnrMeasData_5
          FD14_Log_SnrMeasData_4
          FD14_Log_SnrMeasData_3
          FD14_Log_SnrMeasData_2
          FD14_Log_SnrMeasData_1
          FD14_Log_Sensor_Temperature
          FD14_LMD_rad_Line_4_Heading
          FD14_LMD_rad_Line_3_Heading
          FD14_LMD_rad_Line_2_Heading
          FD14_LMD_rad_Line_1_Heading
          FD14_LMD_px_Line_4_Curvature
          FD14_LMD_px_Line_3_Curvature
          FD14_LMD_px_Line_2_Curvature
          FD14_LMD_px_Line_1_Curvature
          FD14_LMD_pct_Segment_8_Confidence
          FD14_LMD_pct_Segment_7_Confidence
          FD14_LMD_pct_Segment_6_Confidence
          FD14_LMD_pct_Segment_5_Confidence
          FD14_LMD_pct_Segment_4_Confidence
          FD14_LMD_pct_Segment_3_Confidence
          FD14_LMD_pct_Segment_2_Confidence
          FD14_LMD_pct_Segment_1_Confidence
          FD14_LMD_pct_Line_4_Confidence
          FD14_LMD_pct_Line_3_Confidence
          FD14_LMD_pct_Line_2_Confidence
          FD14_LMD_pct_Line_1_Confidence
          FD14_LMD_m_Segment_8_Y2
          FD14_LMD_m_Segment_8_Y1
          FD14_LMD_m_Segment_8_X2
          FD14_LMD_m_Segment_8_X1
          FD14_LMD_m_Segment_7_Y2
          FD14_LMD_m_Segment_7_Y1
          FD14_LMD_m_Segment_7_X2
          FD14_LMD_m_Segment_7_X1
          FD14_LMD_m_Segment_6_Y2
          FD14_LMD_m_Segment_6_Y1
          FD14_LMD_m_Segment_6_X2
          FD14_LMD_m_Segment_6_X1
          FD14_LMD_m_Segment_5_Y2
          FD14_LMD_m_Segment_5_Y1
          FD14_LMD_m_Segment_5_X2
          FD14_LMD_m_Segment_5_X1
          FD14_LMD_m_Segment_4_Y2
          FD14_LMD_m_Segment_4_Y1
          FD14_LMD_m_Segment_4_X2
          FD14_LMD_m_Segment_4_X1
          FD14_LMD_m_Segment_3_Y2
          FD14_LMD_m_Segment_3_Y1
          FD14_LMD_m_Segment_3_X2
          FD14_LMD_m_Segment_3_X1
          FD14_LMD_m_Segment_2_Y2
          FD14_LMD_m_Segment_2_Y1
          FD14_LMD_m_Segment_2_X2
          FD14_LMD_m_Segment_2_X1
          FD14_LMD_m_Segment_1_Y2
          FD14_LMD_m_Segment_1_Y1
          FD14_LMD_m_Segment_1_X2
          FD14_LMD_m_Segment_1_X1
          FD14_LMD_m_Line_4_Start_Range
          FD14_LMD_m_Line_4_Offset
          FD14_LMD_m_Line_4_End_Range
          FD14_LMD_m_Line_3_Start_Range
          FD14_LMD_m_Line_3_Offset
          FD14_LMD_m_Line_3_End_Range
          FD14_LMD_m_Line_2_Start_Range
          FD14_LMD_m_Line_2_Offset
          FD14_LMD_m_Line_2_End_Range
          FD14_LMD_m_Line_1_Start_Range
          FD14_LMD_m_Line_1_Offset
          FD14_LMD_m_Line_1_End_Range
          FD14_LMD_e_Segment_8_ID
          FD14_LMD_e_Segment_7_ID
          FD14_LMD_e_Segment_6_ID
          FD14_LMD_e_Segment_5_ID
          FD14_LMD_e_Segment_4_ID
          FD14_LMD_e_Segment_3_ID
          FD14_LMD_e_Segment_2_ID
          FD14_LMD_e_Segment_1_ID
          FD14_LMD_e_Line_4_Type
          FD14_LMD_e_Line_3_Type
          FD14_LMD_e_Line_2_Type
          FD14_LMD_e_Line_1_Type
          FD14_leLMD_e_HealthStatus
          FD14_LeftDoorRearOpen_Icon_b
          FD14_LeftDoorRearClose_Icon_b
          FD14_LeftDoorFrontOpen_Icon_b
          FD14_LeftDoorFrontClose_Icon_b
          FD14_LeftCam_NA_b
          FD14_LastViewBeforeTestPattern_e
          FD14_LanguageSelection_u8
          FD14_KnobAngle
          FD14_JackknifeThrAngle
          FD14_JackknifeAngle
          FD14_ItbmTrailerStatus
          FD14_isUSSInitSuccess_b
          FD14_IsSlotSel
          FD14_isPLDInitSuccess_b
          FD14_IsParkSftBtnSel
          FD14_IsExitSftBtnSel
          FD14_IsBackSftbtnSel
          FD14_InvalidFeatures_Right_u32
          FD14_InvalidFeatures_Rear_u32
          FD14_InvalidFeatures_Left_u32
          FD14_InvalidFeatures_Front_u32
          FD14_ImageDefeat_Error_e
          FD14_IgnoreVehicleOffSpeed
          FD14_IgnoredFeatures_Right_u32
          FD14_IgnoredFeatures_Rear_u32
          FD14_IgnoredFeatures_Left_u32
          FD14_IgnoredFeatures_Front_u32
          FD14_ignitionStatus_e
          FD14_IeVBII_nfcd_MinDisToCollisionObj
          FD14_IeTRSC_pct_TrlrTrackConf
          FD14_IeTRSC_pct_TrlrRecogConf
          FD14_IeTRSC_pct_TrlrDetConf
          FD14_IeTRSC_M_TRSCStrTrq
          FD14_IeTRSC_m_TrlrWhlBaseEff
          FD14_IeTRSC_kph_VehSpeedVSOSig
          FD14_IeTRSC_e_TRSKMSts
          FD14_IeTRSC_e_TRSKMCenBtnSts
          FD14_IeTRSC_e_TRSKMBtnSts
          FD14_IeTRSC_e_TRSCUnavailReas
          FD14_IeTRSC_e_TRSCAbortReas
          FD14_IeTRSC_e_TrlrRecogInfo
          FD14_IeTRSC_e_TrlrPrsntSts
          FD14_IeTRSC_e_TrlrPrsntFailReas
          FD14_IeTRSC_e_TrlrCalibSts
          FD14_IeTRSC_e_TrlrCalibManState
          FD14_IeTRSC_e_TrlrCalibFailReas
          FD14_IeTRSC_e_TrlrAngGrapOverSts
          FD14_IeTRSC_e_TrailerID
          FD14_IeTRSC_e_GearShiftSts
          FD14_IeTRSC_e_CamBlockSts
          FD14_IeTRSC_deg_TrlrAngKnob
          FD14_IeTRSC_deg_TADAngle
          FD14_IeTRSC_deg_JackknifeThrAngle
          FD14_IeTRSC_deg_FrntWhlAng
          FD14_IeTRSC_cnt_TrlrCalibPassCntCurr
          FD14_IeTRSC_cnt_TrlrCalibPassCnt
          FD14_IeTRSC_cnt_TrlrCalibFailCntCurr
          FD14_IeTRSC_cnt_TrlrCalibFailCnt
          FD14_IeTRSC_cnt_KnobPos
          FD14_IeTHA_e_PamVol
          FD14_IeTHA_e_PamChimeTyp
          FD14_IeTHA_b_ChimeActvRhf
          FD14_IeTHA_b_ChimeActvLhf
          FD14_IeLMD_e_CameraStatus
          FD14_IeAutoPark_e_AlgoState
          FD14_IeAP_e_AutoParkStatus
          FD14_IeAP_e_AbortCon
          FD14_IeAP_cnt_CurrentVehSweep
          FD14_IeAP_cm_RearRightMinXDist_KPI
          FD14_IeAP_cm_RearRightMinXDist
          FD14_IeAP_cm_RearLeftMinXDist_KPI
          FD14_IeAP_cm_RearLeftMinXDist
          FD14_IeAP_cm_RearCenterMinXDist_KPI
          FD14_IeAP_cm_RearCenterMinXDist
          FD14_IeAP_cm_FrntRightMinXDist_KPI
          FD14_IeAP_cm_FrntRightMinXDist
          FD14_IeAP_cm_FrntLeftMinXDist_KPI
          FD14_IeAP_cm_FrntLeftMinXDist
          FD14_IeAP_cm_FrntCenterMinXDist_KPI
          FD14_IeAP_cm_FrntCenterMinXDist
          FD14_IeAP_b_MnvPosOk
          FD14_hitchLength
          FD14_GW_C_I6_timeout_b
          FD14_FSR_overTemp_Fault
          FD14_FSR_MinDistance
          FD14_FSR_hardware_Fault
          FD14_FSR_CommUnknown
          FD14_FSR_comm_Fault
          FD14_FSR_Blockage
          FD14_FSL_overTemp_Fault
          FD14_FSL_MinDistance
          FD14_FSL_hardware_Fault
          FD14_FSL_CommUnknown
          FD14_FSL_comm_Fault
          FD14_FSL_Blockage
          FD14_FrontViewDynamics_b
          FD14_FrontTireTracks_b
          FD14_FrontSensorDetHealth_e
          FD14_FrontFaceCamButtonSelect_b
          FD14_FrontFaceCamButtonNoSelect_b
          FD14_FrontCrossButtonSelect_b
          FD14_FrontCrossButtonNoSelect_b
          FD14_FrontCam_NA_b
          FD14_FRONT_TOP_BTN_PRESSED_b
          FD14_FRONT_CROSS_BTN_PRESSED_b
          FD14_Frameset2AndRearCrossText_b
          FD14_Frameset2AndFrontCrossText_b
          FD14_Frameset1AndTopRearText_b
          FD14_Frameset1AndTopFrontText_b
          FD14_Frame_Index_Lanes__1
          FD14_FOR_overTemp_Fault
          FD14_FOR_MinDistance
          FD14_FOR_hardware_Fault
          FD14_FOR_CommUnknown
          FD14_FOR_comm_Fault
          FD14_FOR_Blockage
          FD14_FOL_overTemp_Fault
          FD14_FOL_MinDistance
          FD14_FOL_hardware_Fault
          FD14_FOL_CommUnknown
          FD14_FOL_comm_Fault
          FD14_FOL_Blockage
          FD14_FiringSnr_TimeStamp
          FD14_FiringMode_TimeStamp
          FD14_Firing_Sensor_Info_R
          FD14_Firing_Sensor_Info_F
          FD14_Firing_Sensor
          FD14_Firing_Mode_Seq
          FD14_FIR_overTemp_Fault
          FD14_FIR_MinDistance
          FD14_FIR_hardware_Fault
          FD14_FIR_CommUnknown
          FD14_FIR_comm_Fault
          FD14_FIR_Blockage
          FD14_FIL_overTemp_Fault
          FD14_FIL_MinDistance
          FD14_FIL_hardware_Fault
          FD14_FIL_CommUnknown
          FD14_FIL_comm_Fault
          FD14_FIL_Blockage
          FD14_FFCV_BTN_PRESSED_b
          FD14_Err_Code_SC_Right
          FD14_Err_Code_SC_Rear
          FD14_Err_Code_SC_Left
          FD14_Err_Code_SC_Front
          FD14_Err_Code_OC_Right
          FD14_Err_Code_OC_Rear
          FD14_Err_Code_OC_Left
          FD14_Err_Code_OC_Front
          FD14_Err_Code_EOL_Rear_Copy_1
          FD14_Err_Code_EOL_Rear
          FD14_Err_Code_EOL_Left
          FD14_Err_Code_EOL_Front
          FD14_EOL_ModuleState_STM_Right
          FD14_EOL_ModuleState_STM_Rear
          FD14_EOL_ModuleState_STM_Left
          FD14_EOL_ModuleState_STM_Front
          FD14_DynOvl_Error_e
          FD14_Debug_Signal_8
          FD14_Debug_Signal_7
          FD14_Debug_Signal_6
          FD14_Debug_Signal_5
          FD14_Debug_Signal_4
          FD14_Debug_Signal_3
          FD14_Debug_Signal_2
          FD14_Debug_Signal_1
          FD14_curState
          FD14_CurrentTrailer_ID
          FD14_Current_Firing_Sequence
          FD14_Curr_TRG_Stat
          FD14_Curr_SystemState_e
          FD14_Curr_RequestedViewByHmiM_e
          FD14_Curr_DisplayedViewByAcore_e
          FD14_crcCvpamFdData1_u8
          FD14_cntrCvpamFdData1_u16
          FD14_CameraDisplaySts2_e
          FD14_CAM_NA_Bitfield_u8
          FD14_CalibStatus_STM_SC_Right
          FD14_CalibStatus_STM_SC_Rear
          FD14_CalibStatus_STM_SC_Left
          FD14_CalibStatus_STM_SC_Front
          FD14_CalibStatus_STM_OC_Right
          FD14_CalibStatus_STM_OC_Rear
          FD14_CalibStatus_STM_OC_Left
          FD14_CalibStatus_STM_OC_Front
          FD14_CalibStatus_STM_EOL_Right
          FD14_CalibStatus_STM_EOL_Rear
          FD14_CalibStatus_STM_EOL_Left
          FD14_CalibStatus_STM_EOL_Front
          FD14_CalibStatus_STM_Current_Right
          FD14_CalibStatus_STM_Current_Rear
          FD14_CalibStatus_STM_Current_Left
          FD14_CalibStatus_STM_Current_Front
          FD14_calibrationSubState
          FD14_calibrationCompleted
          FD14_BumberStatus_Right_Side
          FD14_BumberStatus_Rear
          FD14_BumberStatus_Left_Side
          FD14_BumberStatus_Front
          FD14_BOR_overTemp_Fault
          FD14_BOR_MinDistance
          FD14_BOR_hardware_Fault
          FD14_BOR_CommUnknown
          FD14_BOR_comm_Fault
          FD14_BOR_Blockage
          FD14_BOL_overTemp_Fault
          FD14_BOL_MinDistance
          FD14_BOL_hardware_Fault
          FD14_BOL_CommUnknown
          FD14_BOL_comm_Fault
          FD14_BOL_Blockage
          FD14_BackupRearCamButtonSelect_b
          FD14_BackupRearCamButtonNoSelect_b
          FD14_BackDoorOpen_Icon_b
          FD14_BackCam_NA_b
          FD14_AuxCamButton2Select_b
          FD14_AuxCamButton2NoSelect_b
          FD14_AuxCamButton1Select_b
          FD14_AuxCamButton1NoSelect_b
          FD14_AutoParkInitializedStatus_b
          FD14_AOR_overTemp_Fault
          FD14_AOR_MinDistance
          FD14_AOR_hardware_Fault
          FD14_AOR_CommUnknown
          FD14_AOR_comm_Fault
          FD14_AOR_Blockage
          FD14_AOL_overTemp_Fault
          FD14_AOL_MinDistance
          FD14_AOL_hardware_Fault
          FD14_AOL_CommUnknown
          FD14_AOL_comm_Fault
          FD14_AOL_Blockage
          FD14__JackKnifeAngle
          data-element=FD14_averageIllumination, init-value=0
          data-element=FD14_CsmLocalErrOrEventId, init-value=0
          data-element=FD14_CsmLocalErrOrEventState, init-value=7
          data-element=FD14_CsmLocalModuleId, init-value=15
          data-element=FD14_CsmLocalModuleInstanceId, init-value=0
          data-element=FD14_CsmStateCurrent, init-value=15
          data-element=FD14_CsmStatePrevious, init-value=15
          data-element=FD14_hitchCalibrationAngle, init-value=0
          data-element=FD14_leftCalibrationAngle, init-value=0
          data-element=FD14_MeTRSC_b_OTBLReset, init-value=0
          data-element=FD14_MeTRSC_b_TBLComputationDone, init-value=0
          data-element=FD14_MeTRSC_deg_StrCMD, init-value=0
          data-element=FD14_rightCalibrationAngle, init-value=0
          FD14_ReservedTRSCSig2
          FD14_ReservedTRSCSig1
          FD14_ReservedSignal2
          FD14_ReservedSignal1
          FD14_MeTRSC_s_TRSCTimeTaken
          FD14_MeTRSC_s_TRSCPeriodicity
          FD14_MeTRSC_e_TrlrCalInfoSMVC
          FD14_MeTRSC_deg_TADAngleSMVC
          FD14_MeTRSC_cnt_TRSCAliveCounter
      PpToComSafeFD14Tx: provided-interface=IF_ToComSafeFD14Tx
        provided-com-specs:
          data-element=FD14_Camera_Status, init-value=0
          data-element=FD14_Cntr_ADAS_FD_LANES_1, init-value=0
          data-element=FD14_Cntr_ADAS_FD_LANES_2, init-value=0
          data-element=FD14_FOD_Confidence, init-value=0
          data-element=FD14_Frame_Index_Lanes_1, init-value=0
          data-element=FD14_Frame_Index_Lanes_2, init-value=0
          data-element=FD14_Health_Front_Object_Detection, init-value=0
          data-element=FD14_Health_Lane_Detection, init-value=0
          data-element=FD14_Line_1_Confidence, init-value=0
          data-element=FD14_Line_1_Curvature, init-value=0
          data-element=FD14_Line_1_Curvature_Rate, init-value=0
          data-element=FD14_Line_1_End_Range, init-value=0
          data-element=FD14_Line_1_Heading, init-value=0
          data-element=FD14_Line_1_Offset, init-value=0
          data-element=FD14_Line_1_Start_Range, init-value=0
          data-element=FD14_Line_1_Type, init-value=0
          data-element=FD14_Line_2_Confidence, init-value=0
          data-element=FD14_Line_2_Curvature, init-value=0
          data-element=FD14_Line_2_Curvature_Rate, init-value=0
          data-element=FD14_Line_2_End_Range, init-value=0
          data-element=FD14_Line_2_Heading, init-value=0
          data-element=FD14_Line_2_Offset, init-value=0
          data-element=FD14_Line_2_Start_Range, init-value=0
          data-element=FD14_Line_2_Type, init-value=0
          data-element=FD14_Line_3_Confidence, init-value=0
          data-element=FD14_Line_3_Curvature, init-value=0
          data-element=FD14_Line_3_Curvature_Rate, init-value=0
          data-element=FD14_Line_3_End_Range, init-value=0
          data-element=FD14_Line_3_Heading, init-value=0
          data-element=FD14_Line_3_Offset, init-value=0
          data-element=FD14_Line_3_Start_Range, init-value=0
          data-element=FD14_Line_3_Type, init-value=0
          data-element=FD14_Line_4_Confidence, init-value=0
          data-element=FD14_Line_4_Curvature, init-value=0
          data-element=FD14_Line_4_Curvature_Rate, init-value=0
          data-element=FD14_Line_4_End_Range, init-value=0
          data-element=FD14_Line_4_Heading, init-value=0
          data-element=FD14_Line_4_Offset, init-value=0
          data-element=FD14_Line_4_Start_Range, init-value=0
          data-element=FD14_Line_4_Type, init-value=0
          {data-element=FD14_MAC_ADAS_FD_LANES_1, init-value=[rule-based-values={rule=FILL_UNTIL_END, rule-arguments=0}]}
          {data-element=FD14_MAC_ADAS_FD_LANES_2, init-value=[rule-based-values={rule=FILL_UNTIL_END, rule-arguments=0}]}
          data-element=FD14_ParkingManeuverActive, init-value=0
          data-element=FD14_Reserved_for_functional_safety, init-value=0
          data-element=FD14_Segment_1_Confidence, init-value=0
          data-element=FD14_Segment_1_ID, init-value=0
          data-element=FD14_Segment_1_X1, init-value=0
          data-element=FD14_Segment_1_X2, init-value=0
          data-element=FD14_Segment_1_Y1, init-value=0
          data-element=FD14_Segment_1_Y2, init-value=0
          data-element=FD14_Segment_2_Confidence, init-value=0
          data-element=FD14_Segment_2_ID, init-value=0
          data-element=FD14_Segment_2_X1, init-value=0
          data-element=FD14_Segment_2_X2, init-value=0
          data-element=FD14_Segment_2_Y1, init-value=0
          data-element=FD14_Segment_2_Y2, init-value=0
          data-element=FD14_Segment_3_Confidence, init-value=0
          data-element=FD14_Segment_3_ID, init-value=0
          data-element=FD14_Segment_3_X1, init-value=0
          data-element=FD14_Segment_3_X2, init-value=0
          data-element=FD14_Segment_3_Y1, init-value=0
          data-element=FD14_Segment_3_Y2, init-value=0
          data-element=FD14_Segment_4_Confidence, init-value=0
          data-element=FD14_Segment_4_ID, init-value=0
          data-element=FD14_Segment_4_X1, init-value=0
          data-element=FD14_Segment_4_X2, init-value=0
          data-element=FD14_Segment_4_Y1, init-value=0
          data-element=FD14_Segment_4_Y2, init-value=0
          data-element=FD14_Segment_5_Confidence, init-value=0
          data-element=FD14_Segment_5_ID, init-value=0
          data-element=FD14_Segment_5_X1, init-value=0
          data-element=FD14_Segment_5_X2, init-value=0
          data-element=FD14_Segment_5_Y1, init-value=0
          data-element=FD14_Segment_5_Y2, init-value=0
          data-element=FD14_Segment_6_Confidence, init-value=0
          data-element=FD14_Segment_6_ID, init-value=0
          data-element=FD14_Segment_6_X1, init-value=0
          data-element=FD14_Segment_6_X2, init-value=0
          data-element=FD14_Segment_6_Y1, init-value=0
          data-element=FD14_Segment_6_Y2, init-value=0
          data-element=FD14_Segment_7_Confidence, init-value=0
          data-element=FD14_Segment_7_ID, init-value=0
          data-element=FD14_Segment_7_X1, init-value=0
          data-element=FD14_Segment_7_X2, init-value=0
          data-element=FD14_Segment_7_Y1, init-value=0
          data-element=FD14_Segment_7_Y2, init-value=0
          data-element=FD14_Segment_8_Confidence, init-value=0
          data-element=FD14_Segment_8_ID, init-value=0
          data-element=FD14_Segment_8_X1, init-value=0
          data-element=FD14_Segment_8_X2, init-value=0
          data-element=FD14_Segment_8_Y1, init-value=0
          data-element=FD14_Segment_8_Y2, init-value=0
          data-element=FD14_ManoeuvrePhase, init-value=0
          data-element=FD14_ParkingGearShiftReq, init-value=0
          data-element=FD14_PPPA_AccelMax, init-value=0
          data-element=FD14_PPPA_AccelMin, init-value=0
          data-element=FD14_PPPA_DecelMax, init-value=0
          data-element=FD14_PPPA_DecelMin, init-value=0
          data-element=FD14_PPPA_Interface_BSM, init-value=0
          data-element=FD14_PPPA_JerkAccelMax, init-value=0
          data-element=FD14_PPPA_JerkAccelMin, init-value=0
          data-element=FD14_PPPA_JerkDecelMax, init-value=0
          data-element=FD14_PPPA_JerkDecelMin, init-value=0
          data-element=FD14_PPPA_MaxSpeed, init-value=0
          data-element=FD14_PPPA_StandstillRqst, init-value=0
          data-element=FD14_PPPA_TargetDistance, init-value=0
          data-element=FD14_RR_PAM_Brk_RqSts, init-value=0
          data-element=FD14_RR_PAM_Dist, init-value=0
          data-element=FD14_SPM_Lat_Ctrl_RequestSts, init-value=0
          data-element=FD14_TorqueOverlaySteeringReq_SPM, init-value=1024
      PpToComDbgSafeFD14Tx: provided-interface=IF_ToComDbgSafeFD14Tx
        provided-com-specs:
          data-element=FD14_1_Err_FaultInfo_MCU1_0, init-value=0
          data-element=FD14_1_Err_FaultInfo_MCU2_1, init-value=0
          data-element=FD14_1_Err_FaultInfo_MPU1_0, init-value=0
          data-element=FD14_1_Err_FaultNum_MCU1_0, init-value=0
          data-element=FD14_1_Err_FaultNum_MCU2_0, init-value=0
          data-element=FD14_1_Err_FaultNum_MCU2_1, init-value=0
          data-element=FD14_1_Err_FaultNum_MPU1_0, init-value=0
          data-element=FD14_1_ErrFaultInfo_MCU2_0, init-value=0
          data-element=FD14_1_Reserved_MCU1_0, init-value=0
          data-element=FD14_1_Reserved_MCU2_0, init-value=0
          data-element=FD14_1_Reserved_MCU2_1, init-value=0
          data-element=FD14_1_Reserved_MPU1_0, init-value=0
          data-element=FD14_1_SDL_Fault_MCU1_0, init-value=0
          data-element=FD14_1_SSM_FltData1_MCU1_0, init-value=0
          data-element=FD14_1_SSM_FltData{10..18}_MCU1_0, init-value=0
          data-element=FD14_1_SSM_FltData{2..9}_MCU1_0, init-value=0
          data-element=FD14_1_WDG_Error_ID_MCU1_0, init-value=0
          data-element=FD14_1_Hook_Type_MCU1_0, init-value=0
          data-element=FD14_1_Hook_Service_MCU1_0, init-value=0
          data-element=FD14_1_Hook_Reserved_MCU1_0, init-value=0
          data-element=FD14_1_Hook_PresentPtr_MCU1_0, init-value=0
          data-element=FD14_1_Hook_fatalErr_MCU1_0, init-value=0
          data-element=FD14_1_Hook_Error_MCU1_0, init-value=0
          data-element=FD14_1_Hook_DtErr_MCU1_0, init-value=0
          data-element=FD14_1_Hook_actTsk_MCU1_0, init-value=0
          data-element=FD14_1_TimeSincePowerON, init-value=0
          data-element=FD14_1_SSM_SystemStateReq, init-value=0
          data-element=FD14_1_OsRegMCU_Stack9, init-value=0
          data-element=FD14_1_OsRegMCU_Stack8, init-value=0
          data-element=FD14_1_OsRegMCU_Stack7, init-value=0
          data-element=FD14_1_OsRegMCU_Stack6, init-value=0
          data-element=FD14_1_OsRegMCU_Stack5, init-value=0
          data-element=FD14_1_OsRegMCU_Stack4, init-value=0
          data-element=FD14_1_OsRegMCU_Stack3, init-value=0
          data-element=FD14_1_OsRegMCU_Stack2, init-value=0
          data-element=FD14_1_OsRegMCU_Stack1, init-value=0
          data-element=FD14_1_OsRegMCU_Stack0, init-value=0
          data-element=FD14_1_OsRegMCU_SPSR, init-value=0
          data-element=FD14_1_OsRegMCU_Link, init-value=0
          data-element=FD14_1_OsRegMCU_IFSR, init-value=0
          data-element=FD14_1_OsRegMCU_IFAR, init-value=0
          data-element=FD14_1_OsRegMCU_DFSR, init-value=0
          data-element=FD14_1_OsRegMCU_DFAR, init-value=0
          data-element=FD14_1_OsRegMCU_AIFSR, init-value=0
          data-element=FD14_1_OsRegMCU_ADFSR, init-value=0
          data-element=FD14_1_AliveCntr_MPU1_0, init-value=0
          data-element=FD14_1_AliveCntr_MCU2_1, init-value=0
          data-element=FD14_1_AliveCntr_MCU2_0, init-value=0
    32 x component:
      IoHwAb: type=IoHwAb
      CDD_PMIC: type=CDD_PMIC
      SWC_DIDMgr: type=SWC_DIDMgr
      SWC_DTCMgr: type=SWC_DTCMgr
      SWC_PartNumMgr: type=SWC_PartNumMgr
      SWC_ProxiConfigMgr: type=SWC_ProxiConfigMgr
      SWC_RIDMgr: type=SWC_RIDMgr
      SWC_VoltageMgr: type=SWC_VoltageMgr
      SWC_KinematicModule: type=SWC_KinematicModule
      CDD_GenericBswM: type=CDD_GenericBswM
      CDD_E2EWrapper: type=CDD_E2EWrapper
      CDD_IPCHandler: type=CDD_IPCHandler
      DegManager_B: type=DegManager_B
      DegManager_QM: type=DegManager_QM
      ErrorMgrAgg_1_0_B: type=ErrorMgrAgg_1_0_B
      ErrorMgrAgg_1_0_QM: type=ErrorMgrAgg_1_0_QM
      ErrorMgrSat_1_0_B: type=ErrorMgrSat_1_0_B
      ErrorMgrSat_1_0_QM: type=ErrorMgrSat_1_0_QM
      SSM_Master: type=SSM_Master
      SSM_Slave_1_0: type=SSM_Slave_1_0
      CalDataProvider: type=CalDataProvider
      CDD_WDG: type=CDD_WDG
      CDD_CryptoMgr: type=CDD_CryptoMgr
      SWC_VCANTx: type=SWC_VCANTx
      SWC_VCANRx: type=SWC_VCANRx
      SWC_SafeVCANTx: type=SWC_SafeVCANTx
      SWC_SafeVCANRx: type=SWC_SafeVCANRx
      SWC_WdgFw: type=SWC_WdgFw
      Safety_Guard: type=Safety_Guard
      CDD_Safety: type=CDD_Safety
      Cdd_RunTimeStats_B: type=Cdd_RunTimeStats_B
      Cdd_RunTimeStats_QM: type=Cdd_RunTimeStats_QM
    connect IoHwAb.PpIoHwAbAdc -> SWC_VoltageMgr.RpIoHwAbADCData
    connect SWC_VoltageMgr.PpVoltageChannelStatus -> CDD_GenericBswM.RpVoltageChannelStatus
    connect SWC_DIDMgr.PpIgOnCounter -> SWC_DTCMgr.RpIgOnCounter
    connect SWC_DIDMgr.PpECUTimeSinceIGON -> SWC_DTCMgr.RpECUTimeSinceIGON
    connect SWC_DIDMgr.PpECUTimeStamp -> SWC_DTCMgr.RpECUTimeStamp
    connect ErrorMgrAgg_1_0_B.P_Errors_B -> DegManager_B.R_Errors_B
    connect ErrorMgrAgg_1_0_B.P_Errors_B -> DegManager_QM.R_Errors_B
    connect ErrorMgrAgg_1_0_QM.P_Errors_QM -> DegManager_QM.R_Errors_QM
    connect ErrorMgrSat_1_0_B.P_SatError -> ErrorMgrAgg_1_0_B.R_SatError
    connect ErrorMgrSat_1_0_QM.P_SatError -> ErrorMgrAgg_1_0_QM.R_SatError
    connect CDD_IPCHandler.PpSR_State_QNX -> SSM_Master.R_SSM_QNXState
    connect SSM_Slave_1_0.P_SSM_1_0_State -> SSM_Master.R_SSM_1_0_State
    connect SSM_Master.P_SystemState -> SSM_Slave_1_0.R_SystemState
    connect CDD_IPCHandler.PpSatError_B -> ErrorMgrAgg_1_0_B.R_SatError
    connect CDD_IPCHandler.PpSatError_QM -> ErrorMgrAgg_1_0_QM.R_SatError
    connect CDD_IPCHandler.PpUSSPeriodDiagData -> SWC_DIDMgr.RpUSSPeriodDiagData
    connect CDD_PMIC.PpMCUDeviceRegReadWrite -> SWC_RIDMgr.RpMCUDeviceRegReadWrit
    connect CDD_IPCHandler.PpUSSConstantData -> SWC_DIDMgr.RpUSSConstantData
    connect CDD_IPCHandler.PpSVSOutputToDiagMgr -> SWC_DIDMgr.RpSVSOutputToDiagMgr
    connect CDD_IPCHandler.PpSVSCamSCCalib -> SWC_DIDMgr.RpSVSCamSCCalib
    connect CDD_IPCHandler.PpSVSCamOCCalib -> SWC_DIDMgr.RpSVSCamOCCalib
    connect CDD_IPCHandler.PpSVSCamEOLCalib -> SWC_DIDMgr.RpSVSCamEOLCalib
    connect CDD_IPCHandler.PpSVSCamCurrentCalib -> SWC_DIDMgr.RpSVSCamCurrentCalib
    connect SWC_VoltageMgr.PpReadVoltInfo -> SWC_DIDMgr.RpReadVoltInfo
    connect CDD_IPCHandler.PpNVMCamCalibSM -> SWC_DIDMgr.RpNVMCamCalibSM
    connect SWC_VoltageMgr.PpReadVoltInfo -> SWC_RIDMgr.RpReadVoltInfo
    connect CDD_IPCHandler.PpSVSOutputToDiagMgr -> SWC_RIDMgr.RpSVSOutputToDiagMgr
    connect CDD_IPCHandler.PpSVSToDiag -> SWC_RIDMgr.RpSVSToDiag
    connect ErrorMgrSat_1_0_QM.P_Error -> SWC_ProxiConfigMgr.RpError_CS_QM
    connect ErrorMgrSat_1_0_B.P_Error -> SWC_ProxiConfigMgr.RpError_CS_B
    connect CDD_GenericBswM.PpSystemStateManager -> SWC_DTCMgr.RpSystemStateManager
    connect CDD_IPCHandler.PpCamEepromData -> SWC_DIDMgr.RpCamEepromData
    connect SWC_VoltageMgr.PpTemperatureVal -> SWC_RIDMgr.RpTemperatureVal
    connect CDD_IPCHandler.PpIpcTxData -> SWC_VoltageMgr.RpIpcTxData
    connect ErrorMgrSat_1_0_B.P_Error -> SWC_VoltageMgr.RpError_CS_B
    connect CDD_IPCHandler.PpIpcTxData -> SWC_ProxiConfigMgr.RpIpcTxData
    connect SWC_VoltageMgr.PpReadVoltInfo -> SWC_DTCMgr.RpReadVoltInfo
    connect CDD_IPCHandler.PpSnrDirEcho -> SWC_DIDMgr.RpSnrDirEcho
    connect CDD_GenericBswM.PpGetFirstDTCStatus -> SWC_DIDMgr.RpGetFirstDTCStatus
    connect ErrorMgrSat_1_0_QM.P_Error -> CDD_GenericBswM.RpError_CS
    connect ErrorMgrSat_1_0_QM.P_Error -> CalDataProvider.R_CalDataProvider_ErrorMgrSat_1_0_QM_Error_CS
    connect CDD_IPCHandler.PpSVSCamEOLCalib -> CalDataProvider.R_CalDataProvider_Nvm_SVSCamEOLCalibData
    connect CDD_IPCHandler.PpSVSCamOCCalib -> CalDataProvider.R_CalDataProvider_Nvm_SVSCamOCCalibData
    connect CDD_IPCHandler.PpSVSCamSCCalib -> CalDataProvider.R_CalDataProvider_Nvm_SVSCamSCCalibData
    connect CDD_IPCHandler.PpIpcTxData -> CalDataProvider.R_IPC
    connect CDD_IPCHandler.PpSR_State_MCU2 -> CalDataProvider.R_SSM_2_State
    connect CDD_IPCHandler.PpSR_State_QNX -> CalDataProvider.R_SSM_QNXState
    connect SSM_Master.P_SystemState -> CalDataProvider.R_SystemState
    connect CDD_IPCHandler.PpSVSCamCurrentCalib -> CalDataProvider.R_CalDataProvider_Nvm_SVSCamCurrentCalibData
    connect CalDataProvider.P_CalDataProvider_MCU1_0_Nvm_Data -> SWC_DIDMgr.RpCalDataProviderNvmData
    connect CDD_IPCHandler.PpIpcTxData -> SWC_KinematicModule.RpIpcTxData
    connect CDD_IPCHandler.PpIpcTxData -> SWC_PartNumMgr.RpIpcTxData
    connect CDD_PMIC.PpMCUDeviceRegReadWrite -> CDD_WDG.RpMCUDeviceRegReadWrite
    connect CDD_IPCHandler.PpUSSConstantData -> SWC_PartNumMgr.RpUSSConstantData
    connect CalDataProvider.P_CalDataProvider_Nvm_SVSCamSCCalibData -> SWC_DIDMgr.RpCalDataProvider_Nvm_SVSCamSCCalibData
    connect CalDataProvider.P_CalDataProvider_Nvm_SVSCamOCCalibData -> SWC_DIDMgr.RpCalDataProvider_Nvm_SVSCamOCCalibData
    connect CalDataProvider.P_CalDataProvider_Nvm_SVSCamEOLCalibData -> SWC_DIDMgr.RpCalDataProvider_Nvm_SVSCamEOLCalibData
    connect CalDataProvider.P_CalDataProvider_Nvm_SVSCamCurrentCalibData -> SWC_DIDMgr.RpCalDataProvider_Nvm_SVSCamCurrentCalibData
    connect CDD_IPCHandler.PpIpcTxData -> SSM_Master.R_IPC
    connect CDD_IPCHandler.PpSR_State_MCU2 -> SSM_Master.R_SSM_2_State
    connect SSM_Slave_1_0.P_SSM_1_0_State -> CalDataProvider.R_SSM_1_0_State
    connect CalDataProvider.P_CalDataProvider_Nvm_SVSCamCalibReset -> SWC_RIDMgr.RpSVSCamCalibReset
    connect CDD_PMIC.PpMCUDeviceRegReadWrite -> CDD_GenericBswM.RpMCUDeviceRegReadWrite
    connect SWC_DIDMgr.PpFailsafeDebug -> CDD_WDG.RpFailsafeDebug
    connect CalDataProvider.P_CalDataProvider_MCU1_0_Nvm_Data -> SSM_Slave_1_0.SSM_Slave_1_0_R_SWC_CalDataProvider_MCU1_0_Nvm_Data
    connect SWC_ProxiConfigMgr.PpProxiConfigData -> SSM_Slave_1_0.SSM_Slave_1_0_R_SWC_ProxiM_MCU1_0_EEPROM_Data
    connect CDD_IPCHandler.PpTrscToDiag -> SWC_DIDMgr.RpTrscToDiag
    connect CDD_IPCHandler.PpTrailerDetectOP -> SWC_DIDMgr.RpTrailerDetectOP
    connect CDD_IPCHandler.PpIpcTxData -> DegManager_B.R_IPC
    connect CDD_IPCHandler.PpIpcTxData -> DegManager_QM.R_IPC
    connect CDD_IPCHandler.PpIpcTxData -> SSM_Slave_1_0.R_IPC
    connect CDD_IPCHandler.PpTRSC -> SWC_DIDMgr.RpTRSC
    connect CDD_IPCHandler.PpSMDAInternal -> SWC_DIDMgr.RpSMDAInternal
    connect CDD_IPCHandler.PpVCState -> SWC_DIDMgr.RpVCState
    connect CDD_IPCHandler.PpPAStateOut -> SWC_DIDMgr.RpPAStateOut
    connect CDD_IPCHandler.PpRPAWarnOut -> SWC_DIDMgr.RpRPAWarnOut
    connect IoHwAb.PpUSSDselPin -> SWC_VoltageMgr.RpIoHwAbUSSDselPin
    connect CDD_IPCHandler.PpFeatureOutputsTHA -> SWC_DIDMgr.RpFeatureOutputsTHA
    connect CDD_IPCHandler.PpUssMrrgData -> SWC_PartNumMgr.RpUssMrrgData
    connect CDD_IPCHandler.PpJobFPAData -> SWC_DIDMgr.RpJobFPAData
    connect CDD_IPCHandler.PpJobPLDData -> SWC_DIDMgr.RpJobPLDData
    connect CalDataProvider.P_CalDataProvider_MCU1_0_Nvm_Data -> SWC_RIDMgr.RpCalDataProviderNvmData
    connect CDD_IPCHandler.PpUSSBlockageBit -> SWC_DIDMgr.RpUSSBlockageBit
    connect SWC_ProxiConfigMgr.PpProxiToSWC -> SWC_DIDMgr.RpProxiToSWC
    connect CDD_IPCHandler.PpScreenRequest -> SWC_DIDMgr.RpScreenRequest
    connect SWC_ProxiConfigMgr.PpProxiToSWC -> SWC_VoltageMgr.RpProxiToSWC
    connect CDD_IPCHandler.PpSR_State_QNX -> SWC_ProxiConfigMgr.R_SSM_QNXState
    connect CDD_IPCHandler.PpSR_State_MCU2 -> SWC_ProxiConfigMgr.R_SSM_2_State
    connect SSM_Slave_1_0.P_SSM_1_0_State -> SWC_ProxiConfigMgr.R_SSM_1_0_State
    connect CDD_IPCHandler.PpSR_State_QNX -> SWC_PartNumMgr.R_SSM_QNXState
    connect CDD_IPCHandler.PpSR_State_MCU2 -> SWC_PartNumMgr.R_SSM_2_State
    connect SSM_Slave_1_0.P_SSM_1_0_State -> SWC_PartNumMgr.R_SSM_1_0_State
    connect SWC_ProxiConfigMgr.PpProxiToSWC -> SWC_DTCMgr.RpProxiToSWC
    connect CDD_IPCHandler.PpSvsToVCAN -> SWC_DIDMgr.RpSvsToVCAN
    connect CDD_CryptoMgr.PpCryptoArray -> SWC_DIDMgr.RpCryptoArray
    connect CDD_IPCHandler.PpCpuLoadMcu2_0 -> SWC_DIDMgr.RpCpuLoadMcu2_0
    connect CDD_IPCHandler.PpCpuLoadMcu2_1 -> SWC_DIDMgr.RpCpuLoadMcu2_1
    connect CDD_IPCHandler.PpPointDistOpBuff -> SWC_DIDMgr.RpPointDistOpBuff
    connect CDD_IPCHandler.PpUSSErrorDiagData -> SWC_DIDMgr.RpUSSErrorDiagData
    connect SWC_ProxiConfigMgr.PpVariantData -> CalDataProvider.RpVariantData
    connect SWC_RIDMgr.PpCan14DbgRoutineState -> CDD_IPCHandler.RpCan14DbgRoutineState
    connect CDD_IPCHandler.PpJobTHADetOutput -> SWC_DIDMgr.RpJobTHADetOutput
    connect CDD_IPCHandler.PpSvsToTHA -> SWC_DIDMgr.RpSvsToTHA
    connect ErrorMgrSat_1_0_B.P_Error -> SWC_DIDMgr.RpError_CS_B
    connect ErrorMgrSat_1_0_QM.P_Error -> SWC_DIDMgr.RpError_CS_QM
    connect CDD_IPCHandler.PpWdgCheckpointStatusMcu2_0 -> CDD_WDG.RpWdgCheckpointStatusMcu2_0
    connect CDD_IPCHandler.PpWdgCheckpointStatusMcu2_1 -> CDD_WDG.RpWdgCheckpointStatusMcu2_1
    connect CDD_IPCHandler.PpWdgCheckpointStatusMpu1_0 -> CDD_WDG.RpWdgCheckpointStatusMpu1_0
    connect CDD_IPCHandler.PpSVSNVMData -> CDD_IPCHandler.RpSVSNVMData
    connect CDD_IPCHandler.PpTbFAArbiterOutput -> CDD_IPCHandler.RpTbFAArbiterOutput
    connect CDD_IPCHandler.PpJobFPAData -> CDD_IPCHandler.RpJobFPAData
    connect CDD_IPCHandler.PpFeatureOutputsTHA -> CDD_IPCHandler.RpFeatureOutputsTHA
    connect CDD_IPCHandler.PpDebHmiTrailViews -> CDD_IPCHandler.RpDebHmiTrailViews
    connect CDD_IPCHandler.PpRPAWarnOut -> CDD_IPCHandler.RpRPAWarnOut
    connect CDD_IPCHandler.PpDetInpTrsc -> CDD_IPCHandler.RpDetInpTrsc
    connect CDD_IPCHandler.PpCVPAMFDData -> CDD_IPCHandler.RpCVPAMFDData
    connect CDD_IPCHandler.PpCVPAMFDData2 -> CDD_IPCHandler.RpCVPAMFDData2
    connect CDD_IPCHandler.PpDebCurrDispOverlay -> CDD_IPCHandler.RpDebCurrDispOverlay
    connect CDD_IPCHandler.PpDebCurrDispProxiCfg -> CDD_IPCHandler.RpDebCurrDispProxiCfg
    connect CDD_IPCHandler.PpDebCurReqOverlay -> CDD_IPCHandler.RpDebCurReqOverlay
    connect CDD_IPCHandler.PpDebCurrReqProxiCfg -> CDD_IPCHandler.RpDebCurrReqProxiCfg
    connect CDD_IPCHandler.PpDebHmiInput -> CDD_IPCHandler.RpDebHmiInput
    connect CDD_IPCHandler.PpDebHmiInternal -> CDD_IPCHandler.RpDebHmiInternal
    connect CDD_IPCHandler.PpAPSMPAOut -> CDD_IPCHandler.RpAPSMPAOut
    connect CDD_IPCHandler.PpDriveAssistStatOut -> CDD_IPCHandler.RpDriveAssistStatOut
    connect CDD_IPCHandler.PpFPAWarnOut -> CDD_IPCHandler.RpFPAWarnOut
    connect CDD_IPCHandler.PpJobPLDData -> CDD_IPCHandler.RpJobPLDData
    connect CDD_IPCHandler.PpJobTHADetOutput -> CDD_IPCHandler.RpJobTHADetOutput
    connect CDD_IPCHandler.PpPAStateOut -> CDD_IPCHandler.RpPAStateOut
    connect CDD_IPCHandler.PpPointDistOpBuff -> CDD_IPCHandler.RpPointDistOpBuff
    connect CDD_IPCHandler.PpScreenRequest -> CDD_IPCHandler.RpScreenRequest
    connect CDD_IPCHandler.PpSMDAInternal -> CDD_IPCHandler.RpSMDAInternal
    connect CDD_IPCHandler.PpSvsToTHA -> CDD_IPCHandler.RpSvsToTHA
    connect CDD_IPCHandler.PpSVStoTRSC -> CDD_IPCHandler.RpSVStoTRSC
    connect CDD_IPCHandler.PpSvsToVCAN -> CDD_IPCHandler.RpSvsToVCAN
    connect CDD_IPCHandler.PpTbAPDebugOut -> CDD_IPCHandler.RpTbAPDebugOut
    connect CDD_IPCHandler.PpTbAPSMPAOut -> CDD_IPCHandler.RpTbAPSMPAOut
    connect CDD_IPCHandler.PpTrailerDetectOP -> CDD_IPCHandler.RpTrailerDetectOP
    connect CDD_IPCHandler.PpTRSC -> CDD_IPCHandler.RpTRSC
    connect CDD_IPCHandler.PpTrscSmvctoSvs -> CDD_IPCHandler.RpTrscSmvctoSvs
    connect CDD_IPCHandler.PpTrscToDiag -> CDD_IPCHandler.RpTrscToDiag
    connect CDD_IPCHandler.PpTrscTrlrDet -> CDD_IPCHandler.RpTrscTrlrDet
    connect CDD_IPCHandler.PpUSSBlockageBit -> CDD_IPCHandler.RpUSSBlockageBit
    connect CDD_IPCHandler.PpUssDataCollection -> CDD_IPCHandler.RpUssDataCollection
    connect CDD_IPCHandler.PpUssPointMapGrp -> CDD_IPCHandler.RpUssPointMapGrp
    connect CDD_IPCHandler.PpUssZoneInfo -> CDD_IPCHandler.RpUssZoneInfo
    connect CDD_IPCHandler.PpVCActuatorOut -> CDD_IPCHandler.RpVCActuatorOut
    connect CDD_IPCHandler.PpVCState -> CDD_IPCHandler.RpVCState
    connect CDD_IPCHandler.PpSR_State_MCU2 -> CDD_IPCHandler.RpSR_State_MCU2
    connect CDD_IPCHandler.PpUSSErrorDiagData -> CDD_IPCHandler.RpUSSErrorDiagData
    connect CDD_IPCHandler.PpIJobUSSObjOp -> CDD_IPCHandler.RpIJobUSSObjOp
    connect CDD_IPCHandler.PpNFCDOutput -> CDD_IPCHandler.RpNFCDOutput
    connect CDD_IPCHandler.PpNVMSignMgr -> CDD_IPCHandler.RpNVMSignMgr
    connect CDD_IPCHandler.PpLMDLaneOp -> CDD_IPCHandler.RpLMDLaneOp
    connect CDD_IPCHandler.PpTbTHASmVcDiag -> SWC_DIDMgr.RpTbTHASmVcDiag
    connect CalDataProvider.PpAPVarTunParam -> SWC_KinematicModule.RpAPVarTunParam
    connect CDD_IPCHandler.PpSMDAInternal -> SWC_KinematicModule.RpSMDAInternal
    delegate SWC_VCANRx.RpFromComFD02Rx <-> outer port RpFromComFD02Rx
    delegate SWC_SafeVCANRx.RpFromComSafeFD14Rx <-> outer port RpFromComSafeFD14Rx
    delegate SWC_VCANRx.RpFromComFD14Rx <-> outer port RpFromComFD14Rx
    delegate SWC_SafeVCANTx.PpToComSafeFD02Tx <-> outer port PpToComSafeFD02Tx
    delegate SWC_VCANTx.PpToComFD02Tx <-> outer port PpToComFD02Tx
    connect SWC_VCANRx.PpToSwcFD02Rx -> CalDataProvider.RpToSwcFD02Rx
    connect SWC_VCANRx.PpToSwcFD02Rx -> CDD_GenericBswM.RpToSwcFD02Rx
    connect SWC_SafeVCANRx.PpToSwcSafeFD02Rx -> CDD_GenericBswM.RpToSwcSafeFD02Rx
    connect SWC_VCANRx.PpToSwcFD02Rx -> SWC_DIDMgr.RpToSwcFD02Rx
    connect SWC_VCANRx.PpToSwcFD14Rx -> SWC_DIDMgr.RpToSwcFD14Rx
    connect SWC_SafeVCANRx.PpToSwcSafeFD14Rx -> SWC_DIDMgr.RpToSwcSafeFD14Rx
    connect SWC_SafeVCANRx.PpToSwcSafeFD02Rx -> SWC_DIDMgr.RpToSwcSafeFD02Rx
    connect SWC_VCANRx.PpToSwcFD02Rx -> SWC_DTCMgr.RpToSwcFD02Rx
    connect SWC_VCANRx.PpToSwcFD14Rx -> SWC_DTCMgr.RpToSwcFD14Rx
    connect SWC_SafeVCANRx.PpToSwcSafeFD02Rx -> SWC_DTCMgr.RpToSwcSafeFD02Rx
    connect SWC_SafeVCANRx.PpToSwcSafeFD14Rx -> SWC_DTCMgr.RpToSwcSafeFD14Rx
    connect SWC_SafeVCANRx.PpToSwcSafeFD02Rx -> SWC_KinematicModule.RpToSwcSafeFD02Rx
    connect SWC_SafeVCANRx.PpToSwcSafeFD14Rx -> SWC_KinematicModule.RpToSwcSafeFD14Rx
    delegate SWC_ProxiConfigMgr.RpFromComFD02Rx <-> outer port RpFromComFD02Rx
    connect SWC_VCANRx.PpToSwcFD02Rx -> SWC_RIDMgr.RpToSwcFD02Rx
    connect SWC_SafeVCANRx.PpToSwcSafeFD02Rx -> SWC_RIDMgr.RpToSwcSafeFD02Rx
    connect SWC_SafeVCANRx.PpToSwcSafeFD14Rx -> SWC_RIDMgr.RpToSwcSafeFD14Rx
    delegate SWC_SafeVCANRx.RpFromComSafeFD02Rx <-> outer port RpFromComSafeFD02Rx
    delegate SWC_VCANTx.PpToComFD14Tx <-> outer port PpToComFD14Tx
    delegate SWC_ProxiConfigMgr.PpToComFD02Tx <-> outer port PpToComFD02Tx
    delegate SWC_VCANTx.PpToComDbgFD14Tx <-> outer port PpToComDbgFD14Tx
    delegate SWC_DTCMgr.PpToComFD02Tx <-> outer port PpToComFD02Tx
    connect SWC_VCANTx.PpToSwcFD02Tx -> SWC_DIDMgr.RpToSwcFD02Tx
    connect SWC_VCANTx.PpToSwcFD14Tx -> SWC_DIDMgr.RpToSwcFD14Tx
    connect SWC_SafeVCANTx.PpToSwcSafeFD02Tx -> SWC_DIDMgr.RpToSwcSafeFD02Tx
    connect CDD_GenericBswM.PpToComFD02Tx -> SWC_VCANTx.RpFromSwcFD02Tx
    connect CDD_E2EWrapper.PpE2EServices -> SWC_VCANRx.RpE2EServices
    connect ErrorMgrSat_1_0_B.P_Error -> SWC_VCANRx.RpError_CS_B
    connect ErrorMgrSat_1_0_QM.P_Error -> SWC_VCANRx.RpError_CS_QM
    connect SWC_DIDMgr.PpGearPosition -> SWC_VCANRx.RpGearPosition
    connect CDD_IPCHandler.PpIpcTxData -> SWC_VCANRx.RpIpcTxData
    connect CDD_IPCHandler.PpIpcTxData -> SWC_SafeVCANRx.RpIpcTxData
    connect CDD_IPCHandler.PpCVPAMFDData -> SWC_SafeVCANTx.RpCVPAMFDData
    connect CDD_IPCHandler.PpCVPAMFDData2 -> SWC_SafeVCANTx.RpCVPAMFDData2
    connect CDD_IPCHandler.PpDriveAssistStatOut -> SWC_SafeVCANTx.RpDriveAssistStatOut
    connect CDD_IPCHandler.PpFPAWarnOut -> SWC_SafeVCANTx.RpFPAWarnOut
    connect CDD_IPCHandler.PpPAStateOut -> SWC_SafeVCANTx.RpPAStateOut
    connect CDD_IPCHandler.PpRPAWarnOut -> SWC_SafeVCANTx.RpRPAWarnOut
    connect CDD_IPCHandler.PpSvsToVCAN -> SWC_SafeVCANTx.RpSvsToVCAN
    connect CDD_IPCHandler.PpTbAPDebugOut -> SWC_SafeVCANTx.RpTbAPDebugOut
    connect CDD_IPCHandler.PpTbAPSMPAOut -> SWC_SafeVCANTx.RpTbAPSMPAOut
    connect CDD_IPCHandler.PpTbFAArbiterOutput -> SWC_SafeVCANTx.RpTbFAArbiterOutput
    connect CDD_IPCHandler.PpTRSC -> SWC_SafeVCANTx.RpTRSC
    connect CDD_IPCHandler.PpAPSMPAOut -> SWC_VCANTx.RpAPSMPAOut
    connect SWC_RIDMgr.PpCan14DbgRoutineState -> SWC_VCANTx.RpCan14DbgRoutineState
    connect CDD_IPCHandler.PpCVPAMFDData -> SWC_VCANTx.RpCVPAMFDData
    connect CDD_IPCHandler.PpCVPAMFDData2 -> SWC_VCANTx.RpCVPAMFDData2
    connect CDD_IPCHandler.PpDebCurrDispOverlay -> SWC_VCANTx.RpDebCurrDispOverlay
    connect CDD_IPCHandler.PpDebCurrDispProxiCfg -> SWC_VCANTx.RpDebCurrDispProxiCfg
    connect CDD_IPCHandler.PpDebCurReqOverlay -> SWC_VCANTx.RpDebCurReqOverlay
    connect CDD_IPCHandler.PpDebCurrReqProxiCfg -> SWC_VCANTx.RpDebCurrReqProxiCfg
    connect CDD_IPCHandler.PpDebHmiInput -> SWC_VCANTx.RpDebHmiInput
    connect CDD_IPCHandler.PpDebHmiInternal -> SWC_VCANTx.RpDebHmiInternal
    connect CDD_IPCHandler.PpDebHmiTrailViews -> SWC_VCANTx.RpDebHmiTrailViews
    connect CDD_IPCHandler.PpDetInpTrsc -> SWC_VCANTx.RpDetInpTrsc
    connect CDD_IPCHandler.PpDriveAssistStatOut -> SWC_VCANTx.RpDriveAssistStatOut
    connect CDD_IPCHandler.PpFeatureOutputsTHA -> SWC_VCANTx.RpFeatureOutputsTHA
    connect CDD_IPCHandler.PpFPAWarnOut -> SWC_VCANTx.RpFPAWarnOut
    connect CDD_IPCHandler.PpIJobUSSObjOp -> SWC_VCANTx.RpIJobUSSObjOp
    connect CDD_IPCHandler.PpJobPLDData -> SWC_VCANTx.RpJobPLDData
    connect CDD_IPCHandler.PpJobFPAData -> SWC_VCANTx.RpJobFPAData
    connect CDD_IPCHandler.PpJobTHADetOutput -> SWC_VCANTx.RpJobTHADetOutput
    connect CDD_IPCHandler.PpLMDLaneOp -> SWC_VCANTx.RpLMDLaneOp
    connect CDD_IPCHandler.PpNFCDOutput -> SWC_VCANTx.RpNFCDOutput
    connect CDD_IPCHandler.PpNVMSignMgr -> SWC_VCANTx.RpNVMSignMgr
    connect CDD_IPCHandler.PpPAStateOut -> SWC_VCANTx.RpPAStateOut
    connect CDD_IPCHandler.PpPointDistOpBuff -> SWC_VCANTx.RpPointDistOpBuff
    connect CDD_IPCHandler.PpRPAWarnOut -> SWC_VCANTx.RpRPAWarnOut
    connect CDD_IPCHandler.PpScreenRequest -> SWC_VCANTx.RpScreenRequest
    connect CDD_IPCHandler.PpSMDAInternal -> SWC_VCANTx.RpSMDAInternal
    connect CDD_IPCHandler.PpSR_State_MCU2 -> SWC_VCANTx.RpSR_State_MCU2
    connect CDD_IPCHandler.PpSVSNVMData -> SWC_VCANTx.RpSVSNVMData
    connect CDD_IPCHandler.PpSvsToTHA -> SWC_VCANTx.RpSvsToTHA
    connect CDD_IPCHandler.PpSVStoTRSC -> SWC_VCANTx.RpSVStoTRSC
    connect CDD_IPCHandler.PpSvsToVCAN -> SWC_VCANTx.RpSvsToVCAN
    connect CDD_IPCHandler.PpTbAPDebugOut -> SWC_VCANTx.RpTbAPDebugOut
    connect CDD_IPCHandler.PpTbAPSMPAOut -> SWC_VCANTx.RpTbAPSMPAOut
    connect CDD_IPCHandler.PpTbFAArbiterOutput -> SWC_VCANTx.RpTbFAArbiterOutput
    connect CDD_IPCHandler.PpTrailerDetectOP -> SWC_VCANTx.RpTrailerDetectOP
    connect CDD_IPCHandler.PpTRSC -> SWC_VCANTx.RpTRSC
    connect CDD_IPCHandler.PpTrscSmvctoSvs -> SWC_VCANTx.RpTrscSmvctoSvs
    connect CDD_IPCHandler.PpTrscToDiag -> SWC_VCANTx.RpTrscToDiag
    connect CDD_IPCHandler.PpTrscTrlrDet -> SWC_VCANTx.RpTrscTrlrDet
    connect CDD_IPCHandler.PpUSSBlockageBit -> SWC_VCANTx.RpUSSBlockageBit
    connect CDD_IPCHandler.PpUssDataCollection -> SWC_VCANTx.RpUssDataCollection
    connect CDD_IPCHandler.PpUSSErrorDiagData -> SWC_VCANTx.RpUSSErrorDiagData
    connect CDD_IPCHandler.PpUssPointMapGrp -> SWC_VCANTx.RpUssPointMapGrp
    connect CDD_IPCHandler.PpUssZoneInfo -> SWC_VCANTx.RpUssZoneInfo
    connect CDD_IPCHandler.PpVCActuatorOut -> SWC_VCANTx.RpVCActuatorOut
    connect CDD_IPCHandler.PpVCState -> SWC_VCANTx.RpVCState
    connect CDD_IPCHandler.PpIpcTxData -> SWC_RIDMgr.RpIpcTxData
    delegate SWC_SafeVCANTx.PpToComSafeFD14Tx <-> outer port PpToComSafeFD14Tx
    connect SWC_SafeVCANTx.PpToSwcSafeFD14Tx -> SWC_DIDMgr.RpToSwcSafeFD14Tx
    connect ErrorMgrSat_1_0_B.P_Error -> SWC_SafeVCANRx.RpError_CS_B
    connect CDD_E2EWrapper.PpE2EServices -> SWC_SafeVCANRx.RpE2EServices
    connect CDD_E2EWrapper.PpE2EServices -> SWC_SafeVCANTx.RpE2EServices
    connect CDD_E2EWrapper.PpE2EServices -> SWC_VCANTx.RpE2EServices
    connect CDD_IPCHandler.PpVCActuatorOut -> SWC_SafeVCANTx.RpVCActuatorOut
    connect CDD_IPCHandler.PpAPSMPAOut -> SWC_SafeVCANTx.RpAPSMPAOut
    connect SWC_DIDMgr.PpSleepProcessState -> CDD_GenericBswM.RpSleepProcessState
    connect CDD_IPCHandler.PpIDebugFODObject -> CDD_IPCHandler.RpIDebugFODObject
    connect CDD_IPCHandler.PpIFODOpArbitration -> CDD_IPCHandler.RpIFODOpArbitration
    connect CDD_IPCHandler.PpMEProxi -> CDD_IPCHandler.RpMEProxi
    connect CDD_IPCHandler.PpTbFAResetKM -> CDD_IPCHandler.RpTbFAResetKM
    connect SWC_ProxiConfigMgr.Pp_2023_ProxiData -> SWC_DIDMgr.Rp2023_ProxiData
    connect CDD_IPCHandler.PpCamCsData -> SWC_DIDMgr.RpCamCsData
    connect CDD_IPCHandler.PpMEProxi -> SWC_DIDMgr.RpMEProxi
    connect SWC_RIDMgr.PpPlantMode -> SWC_DIDMgr.RpPlantMode
    connect SWC_ProxiConfigMgr.PpProxiConfigData -> SWC_DIDMgr.RpProxiConfigData
    connect SWC_ProxiConfigMgr.PpProxiErrorData -> SWC_DIDMgr.RpProxiErrorData
    connect SWC_VoltageMgr.PpUssPowerData -> SWC_DIDMgr.RpUssPowerData
    connect SWC_RIDMgr.PpSnsrFnctnlTstFlg -> SWC_DTCMgr.PpRpSnsrFnctnlTstFlg
    connect CDD_IPCHandler.PpIFODOpArbitration -> SWC_KinematicModule.RpIFODOpArbitration
    connect CDD_IPCHandler.PpTbFAResetKM -> SWC_KinematicModule.RpTbFAResetKM
    connect CDD_IPCHandler.PpMEProxi -> SWC_ProxiConfigMgr.RpMEProxi
    connect SWC_DIDMgr.PpGearPosition -> SWC_SafeVCANRx.RpGearPosition
    connect SWC_ProxiConfigMgr.PpProxiReset -> CDD_GenericBswM.RpProxiReset
    connect CDD_IPCHandler.PpIpcTxData -> SWC_DIDMgr.RpIpcTxData
    connect SWC_RIDMgr.PpFailSafeReaction -> SWC_SafeVCANRx.RpFailSafeReaction
    connect SWC_RIDMgr.PpFailSafeReaction -> SWC_VCANRx.RpFailSafeReaction
    connect ErrorMgrAgg_1_0_B.P_SafeState -> Safety_Guard.R_SafeState_B
    connect ErrorMgrAgg_1_0_QM.P_SafeState -> Safety_Guard.R_SafeState_QM
    connect CDD_IPCHandler.PpCVPAMFDData -> Safety_Guard.RpCVPAMFDData
    connect CDD_IPCHandler.PpCVPAMFDData2 -> Safety_Guard.RpCVPAMFDData2
    connect CDD_IPCHandler.PpPAStateOut -> Safety_Guard.RpPAStateOut
    connect CDD_IPCHandler.PpVCActuatorOut -> Safety_Guard.RpVCActuatorOut
    connect Safety_Guard.PpSafeGuardCVPAMFDData2 -> SWC_SafeVCANTx.RpSafeGuardCVPAMFDData2
    connect Safety_Guard.PpSafeGuardCVPAMFDData -> SWC_SafeVCANTx.RpSafeGuardCVPAMFDData
    connect Safety_Guard.PpSafeGuardPAStateOut -> SWC_SafeVCANTx.RpSafeGuardPAStateOut
    connect Safety_Guard.PpSafeGuardVCActuatorOut -> SWC_SafeVCANTx.RpSafeGuardVCActuatorOut
    connect CDD_IPCHandler.PpCamSerENStat -> SWC_DIDMgr.RpCamSerENStat
    connect SWC_DTCMgr.PpClearDTCSettingStatus -> SWC_DIDMgr.RpClearDTCSettingStatus
    connect SWC_SafeVCANRx.PpToSwcSafeFD02Rx -> CDD_IPCHandler.RpToSwcSafeFD02Rx
    connect CDD_IPCHandler.PpSvsToVCAN -> Safety_Guard.RpSvsToVCAN
    connect Safety_Guard.PpSafeGuardSvsToVCAN -> SWC_SafeVCANTx.RpSafeGuardSvsToVCAN
    connect SWC_VCANRx.PpVcanRxQM -> SWC_SafeVCANRx.RpVcanRxQM
    connect SWC_ProxiConfigMgr.PpProxiToSWC -> SWC_SafeVCANRx.RpProxiToSWC
    connect SWC_ProxiConfigMgr.PpProxiConfigData -> SWC_SafeVCANRx.RpProxiConfigData
    connect CDD_IPCHandler.PpSR_State_MCU2 -> SWC_SafeVCANRx.R_SSM_2_State
    connect CDD_IPCHandler.PpSR_State_QNX -> SWC_SafeVCANRx.R_SSM_QNXState
    connect CDD_IPCHandler.PpMEProxi -> SWC_SafeVCANRx.RpMEProxi
    connect SWC_ProxiConfigMgr.PpProxiConfigData -> SWC_KinematicModule.RpProxiConfigData
    connect SWC_DIDMgr.PpFailsafeAction -> Safety_Guard.RpFailsafeAction
    connect CDD_IPCHandler.PpKeepAliveResponse -> CDD_WDG.RpKeepAliveResponse
    connect Safety_Guard.PpSafeState2RSTReason -> SWC_DIDMgr.RpSafeState2RSTReason
    connect SWC_RIDMgr.PpCalibRoutineTrigger -> CalDataProvider.RpCalibRoutineTrigger
    connect ErrorMgrSat_1_0_B.P_Error -> CalDataProvider.RpError_CS_B
    connect CDD_IPCHandler.PpCamEepromData -> CalDataProvider.RpCamEepromData
    connect CDD_IPCHandler.PpMEProxi -> CalDataProvider.RpMEProxi
    connect SWC_ProxiConfigMgr.PpProxiToSWC -> CalDataProvider.RpProxiToSWC
    connect SWC_PartNumMgr.PpFlashSts -> CDD_CryptoMgr.RpFlashSts
    connect SWC_ProxiConfigMgr.PpProxiConfigData -> CDD_CryptoMgr.RpProxiConfigData
    connect CDD_IPCHandler.PpTRSCSMVCtoDebug -> SWC_VCANTx.RpTRSCSMVCtoDebug
    connect CDD_IPCHandler.PpUsCsmStatCngRsn -> SWC_VCANTx.RpUsCsmStatCngRsn
    connect CDD_IPCHandler.PpUSSPeriodDiagData -> SWC_VCANTx.RpUSSPeriodDiagData
    connect SSM_Master.P_SystemState -> SWC_ProxiConfigMgr.R_SystemState
    connect SSM_Master.P_SystemState -> SWC_SafeVCANRx.R_SystemState
    connect SSM_Master.P_SystemState -> SWC_PartNumMgr.R_SystemState
    connect CDD_IPCHandler.PpAPSMPAOut -> SWC_DTCMgr.RpAPSMPAOut
    connect CDD_IPCHandler.PpUssDebugMsg -> SWC_VCANTx.RpUssDebugMsg
    connect SWC_DIDMgr.PpFailsafeDebug -> SSM_Master.RpFailsafeDebug
    connect DegManager_QM.P_FID_Output_QM -> SWC_VCANTx.RpFID_Output_QM
    connect SWC_DIDMgr.PpResetNvmFlag -> CalDataProvider.RpResetNvmFlag
    connect CDD_IPCHandler.PpCAMSelInfo -> SWC_VoltageMgr.RpCAMSelInfo
    delegate SWC_SafeVCANTx.PpToComDbgSafeFD14Tx <-> outer port PpToComDbgSafeFD14Tx
    connect CDD_IPCHandler.PpErrFltMcu2_0 -> SWC_SafeVCANTx.RpErrFltMcu2_0
    connect CDD_IPCHandler.PpErrFltMcu2_1 -> SWC_SafeVCANTx.RpErrFltMcu2_1
    connect CDD_IPCHandler.PpErrFltMpu1_0 -> SWC_SafeVCANTx.RpErrFltMpu1_0
    connect ErrorMgrAgg_1_0_B.P_DtcData -> SWC_VoltageMgr.R_DtcData_B
    connect CDD_IPCHandler.PpAPSMPAOut -> SWC_SafeVCANRx.RpAPSMPAOut
    connect CDD_IPCHandler.PpDriveAssistStatOut -> SWC_SafeVCANRx.RpDriveAssistStatOut
    connect CDD_IPCHandler.PpFeatureOutputsTHA -> SWC_SafeVCANRx.RpFeatureOutputsTHA
    connect CDD_IPCHandler.PpTRSC -> SWC_SafeVCANRx.RpTRSC
    connect CDD_IPCHandler.PpTRSC -> SWC_VCANRx.RpTRSC
    connect Safety_Guard.PpSafeGuardPAStateOut -> SWC_SafeVCANRx.RpSafeGuardPAStateOut
    connect Safety_Guard.PpSafeGuardSvsToVCAN -> SWC_SafeVCANRx.RpSafeGuardSvsToVCAN
    connect SWC_VCANRx.PpBusOffIndication -> SWC_VCANTx.RpBusOffIndication
    connect SSM_Master.P_SystemState -> CDD_Safety.R_SystemState
    connect ErrorMgrSat_1_0_QM.P_Error -> CDD_Safety.R_Error_QM
    connect ErrorMgrSat_1_0_B.P_Error -> CDD_Safety.R_Error_B
    connect SWC_ProxiConfigMgr.PpProxiToSWC -> SWC_RIDMgr.RpProxiToSWC
    connect CDD_IPCHandler.PpSR_State_MCU2 -> SWC_RIDMgr.R_SSM_2_State
    connect SWC_DIDMgr.Pp_PlantOdoData -> CalDataProvider.Rp_PlantOdoData
    connect SWC_RIDMgr.PpPlantMode -> SWC_SafeVCANRx.RpPlantMode
    connect CDD_IPCHandler.PpIpcTxData -> SWC_DTCMgr.RpIpcTxData
    connect Cdd_RunTimeStats_QM.PpRunTimeStatCSData -> SWC_DIDMgr.RpRunTimeStatCSData
    connect SWC_DIDMgr.PpPerformanceStatsEnable -> Cdd_RunTimeStats_B.RpPerformanceStatsEnable
    connect SWC_DIDMgr.PpPerformanceStatsEnable -> Cdd_RunTimeStats_QM.RpPerformanceStatsEnable
    connect CDD_IPCHandler.PpWdgCheckpointStatusMcu2_0 -> SWC_SafeVCANTx.RpWdgCheckpointStatusMcu2_0
    connect CDD_IPCHandler.PpWdgCheckpointStatusMcu2_1 -> SWC_SafeVCANTx.RpWdgCheckpointStatusMcu2_1
    connect CDD_IPCHandler.PpWdgCheckpointStatusMpu1_0 -> SWC_SafeVCANTx.RpWdgCheckpointStatusMpu1_0
    connect CDD_IPCHandler.PpKeepAliveResponse -> SWC_SafeVCANTx.RpKeepAliveResponse
    connect SSM_Master.P_SystemState -> SWC_SafeVCANTx.R_SystemState
    connect CDD_GenericBswM.PpNmStateInfo -> SWC_SafeVCANRx.RpNmStateInfo
    connect SWC_DTCMgr.PpDtcB12852AData -> SWC_SafeVCANRx.RpDtcB12852AData
    connect CDD_IPCHandler.PpPAM2BTIpcTxStatus -> SWC_SafeVCANRx.RpPAM2BTIpcTxStatus
package /EndToEndProtections
  end to end protection set EndToEndProtectionSet
